AUTOSAR XML (schema 00047)
standard types defined: boolean_DataConstr, boolean, float32, sint16, uint16, uint32, uint8
package /Constants
  constant specification InitValue_SeatAxPosStrct: value-spec={short-label=InitValue_SeatAxPosStrct, fields=[seatID:SeatID_NULL, {short-label=seatPositionCounts, fields=[hdrstForeaft:0, hdrstHght:0, seatHght:0, seatForeaft:0, seatRcln:0, lmbrHzntl:0, lmbrVert:0, thighLeft:0, thighRight:0, cshnTlt:0, thorPvt:0, calfRst:0, foreaftExt:0, seatSwivel:0, centerStackConsole:0]}, {short-label=seatPositionPercent, fields=[hdrstForeaft:0, hdrstHght:0, seatHght:0, seatForeaft:0, seatRcln:0, lmbrHzntl:0, lmbrVert:0, thighLeft:0, thighRight:0, cshnTlt:0, thorPvt:0, calfRst:0, foreaftExt:0, seatSwivel:0, centerStackConsole:0]}, {short-label=seatPositionPhysicalUnits, fields=[hdrstForeaft:0, hdrstHght:0, seatHght:0, seatForeaft:0, seatRcln:0, lmbrHzntl:0, lmbrVert:0, thighLeft:0, thighRight:0, cshnTlt:0, thorPvt:0, calfRst:0, foreaftExt:0, seatSwivel:0, centerStackConsole:0]}]}
  constant specification InitValue_SeatAxisStatStrct: value-spec={short-label=InitValue_SeatAxisStatStrct, fields=[seatID:SeatID_NULL, hdrstForeaftStat:SeatAxisStatus_NULL, hdrstHghtStat:SeatAxisStatus_NULL, seatHghtStat:SeatAxisStatus_NULL, seatForeaftStat:SeatAxisStatus_NULL, seatRclnStat:SeatAxisStatus_NULL, lmbrHzntlStat:SeatAxisStatus_NULL, lmbrVertStat:SeatAxisStatus_NULL, thighLeftStat:SeatAxisStatus_NULL, thighRightStat:SeatAxisStatus_NULL, cshnTltStat:SeatAxisStatus_NULL, thorPvtStat:SeatAxisStatus_NULL, calfRstStat:SeatAxisStatus_NULL, foreaftExtStat:SeatAxisStatus_NULL, seatSwivelStat:SeatAxisStatus_NULL, centerConsoleStat:SeatAxisStatus_NULL]}
  constant specification InitValue_SeatsTargetAxisStruct: value-spec={short-label=InitValue_SeatsTargetAxisStruct, fields=[selectedSeatMenu:SeatID_NULL, {short-label=positionAxisID, fields=[firstRowSeatDriverPositionAxisID:MultifunctionAxes_MASSAGE_PATTERN_01, firstRowSeatPassengerPositionAxisID:MultifunctionAxes_MASSAGE_PATTERN_01, secondRowSeatDriverPositionAxisID:MultifunctionAxes_MASSAGE_PATTERN_01, secondRowSeatPassengerPositionAxisID:MultifunctionAxes_MASSAGE_PATTERN_01]}]}
package /DataConstraints
  range boolean_DataConstr1: raw 0..1
package /DataTypeMappingSets
  4 x data type mapping set:
    DataMappings  # Data Mappings
    FoundationSwDataMapping
    SeatMapping
      data-type-maps:
        application-data-type=ActuationDutyCycle, implementation-data-type=uint8
        application-data-type=ActuationDutyCycle1, implementation-data-type=uint8
        application-data-type=AvailSeatAxType, implementation-data-type=uint32
        application-data-type=AvailSeatBldrPos, implementation-data-type=uint8
        application-data-type=AvailSeatCtlType, implementation-data-type=uint8
        application-data-type=AvailSeatFldPtchType, implementation-data-type=uint8
        application-data-type=AvailStmsPtrn, implementation-data-type=uint16
        application-data-type=CafRst, implementation-data-type=sint16
        application-data-type=ForeaftExten, implementation-data-type=uint16
        application-data-type=Int16AbsoluteValue, implementation-data-type=uint16
        application-data-type=Int32CountValue, implementation-data-type=uint16
        application-data-type=ManPrsHoldStat, implementation-data-type=uint8
        application-data-type=MultifunctionAxes, implementation-data-type=uint8
        application-data-type=MvtDir, implementation-data-type=uint8
        application-data-type=RelPrio, implementation-data-type=uint16
        application-data-type=SeatAdjmt, implementation-data-type=sint16
        application-data-type=SeatAdjsmt, implementation-data-type=uint8
        application-data-type=SeatAft, implementation-data-type=uint16
        application-data-type=SeatAxPercent, implementation-data-type=uint8
        application-data-type=SeatAxPosCntStrct, implementation-data-type=SeatAxPosCntStrct
        application-data-type=SeatAxPosStrct, implementation-data-type=SeatAxPosStrct
        application-data-type=SeatAxStatStrct, implementation-data-type=SeatAxStatStrct
        application-data-type=SeatAxType, implementation-data-type=uint8
        application-data-type=SeatAxVal, implementation-data-type=sint16
        application-data-type=SeatAxisStatus, implementation-data-type=uint8
        application-data-type=SeatAxisType, implementation-data-type=uint8
        application-data-type=SeatBlMovmt, implementation-data-type=sint16
        application-data-type=SeatBldrPActl, implementation-data-type=uint8
        application-data-type=SeatBldrPDsply, implementation-data-type=uint8
        application-data-type=SeatBldrPos, implementation-data-type=uint8
        application-data-type=SeatBldrStatArr, implementation-data-type=SeatBldrStatArr
        application-data-type=SeatBldrStatStrct, implementation-data-type=SeatBldrStatStrct
        application-data-type=SeatClimtMde, implementation-data-type=uint8
        application-data-type=SeatClimtStatArr, implementation-data-type=SeatClimtStatArr
        application-data-type=SeatClimtStatStrct, implementation-data-type=SeatClimtStatStrct
        application-data-type=SeatCntToDeg, implementation-data-type=sint16
        application-data-type=SeatCntToMm, implementation-data-type=sint16
        application-data-type=SeatCntToPct, implementation-data-type=sint16
        application-data-type=SeatCpbltyArr, implementation-data-type=SeatCpbltyArr
        application-data-type=SeatCpbltyStrct, implementation-data-type=SeatCpbltyStrct
        application-data-type=SeatCtlChngStat, implementation-data-type=uint8
        application-data-type=SeatDegCnvrtOfstStrct, implementation-data-type=SeatDegCnvrtOfstStrct
        application-data-type=SeatDegCnvrtScalStrct, implementation-data-type=SeatDegCnvrtScalStrct
        application-data-type=SeatFaltStatStrct, implementation-data-type=SeatFltStatStrct
        application-data-type=SeatFldStat, implementation-data-type=uint8
        application-data-type=SeatFldStatArr, implementation-data-type=SeatFldStatArr
        application-data-type=SeatFldStatStrct, implementation-data-type=SeatFldStatStrct
        application-data-type=SeatFldType, implementation-data-type=uint8
        application-data-type=SeatFltStatArr, implementation-data-type=SeatFltStatArr
        application-data-type=SeatFoldStat, implementation-data-type=uint8
        application-data-type=SeatForeaft, implementation-data-type=sint16
        application-data-type=SeatHdrstStatArr, implementation-data-type=SeatHdrstStatArr
        application-data-type=SeatHdrstStatStrct, implementation-data-type=SeatHdrstStatStrct
        application-data-type=SeatID, implementation-data-type=uint8
        application-data-type=SeatID1, implementation-data-type=uint8
        application-data-type=SeatId2, implementation-data-type=uint8
        application-data-type=SeatLmbrMovmt, implementation-data-type=sint16
        application-data-type=SeatLmbrMovmt1, implementation-data-type=uint8
        application-data-type=SeatMMCnvrtOfstStrct, implementation-data-type=SeatMMCnvrtOfstStrct
        application-data-type=SeatMMCnvrtScalStrct, implementation-data-type=SeatMMCnvrtScalStrct
        application-data-type=SeatMvmtType, implementation-data-type=uint8
        application-data-type=SeatMvtDir, implementation-data-type=uint8
        application-data-type=SeatMvtType, implementation-data-type=uint8
        application-data-type=SeatOccStat, implementation-data-type=uint8
        application-data-type=SeatOccStatArr, implementation-data-type=SeatOccStatArr
        application-data-type=SeatOccStatStrct, implementation-data-type=SeatOccStatStrct
        application-data-type=SeatPctCnvrtOfstStrct, implementation-data-type=SeatPctCnvrtOfstStrct
        application-data-type=SeatPctCnvrtScalStrct, implementation-data-type=SeatPctCnvrtScalStrct
        application-data-type=SeatPosArr, implementation-data-type=SeatPosArr
        application-data-type=SeatPosDutCyclStrct, implementation-data-type=SeatPosDutCyclStrct
        application-data-type=SeatRcln, implementation-data-type=sint16
        application-data-type=SeatRecline, implementation-data-type=uint8
        application-data-type=SeatRelPrio, implementation-data-type=uint16
        application-data-type=SeatSetPoint, implementation-data-type=uint8
        application-data-type=SeatSetStat, implementation-data-type=sint16
        application-data-type=SeatSetStatArr, implementation-data-type=SeatSetngStatArr
        application-data-type=SeatSetStatStrct, implementation-data-type=SeatSetngStatStrct
        application-data-type=SeatSrvcSint16, implementation-data-type=sint16
        application-data-type=SeatSrvcUint16, implementation-data-type=uint16
        application-data-type=SeatSrvcUint32, implementation-data-type=uint32
        application-data-type=SeatSrvcUint8, implementation-data-type=uint8
        application-data-type=SeatStmsIntns, implementation-data-type=uint8
        application-data-type=SeatStmsMde, implementation-data-type=uint8
        application-data-type=SeatSwiv, implementation-data-type=uint16
        application-data-type=SeatSwtchMvtDir, implementation-data-type=uint8
        application-data-type=SeatsTargetAxisStruct, implementation-data-type=SeatsTargetAxisStruct
        application-data-type=Sint16, implementation-data-type=sint16
        application-data-type=StmsIntns, implementation-data-type=uint8
        application-data-type=StmsMde, implementation-data-type=uint8
        application-data-type=StmsPtrn, implementation-data-type=uint8
        application-data-type=StmsStatArr, implementation-data-type=StmsStatArr
        application-data-type=StmsStatStrct, implementation-data-type=StmsStatStrct
        application-data-type=Unit, implementation-data-type=uint8
        application-data-type=VehSpd, implementation-data-type=float32
        application-data-type=boolean, implementation-data-type=boolean
        application-data-type=mSecUint32, implementation-data-type=uint32
        application-data-type=Int16AbsoluteValue_n32768ton1, implementation-data-type=uint16
        application-data-type=SeatAxPosNoUntStrct, implementation-data-type=SeatAxPosNoUntStrct
        application-data-type=SeatPosUnitStrct, implementation-data-type=SeatPosUnitStrct
        application-data-type=SeatAxisStatStrct, implementation-data-type=SeatAxisStatStrct
        application-data-type=ActuationDutyCycle1_0to255, implementation-data-type=uint8
        application-data-type=ErrorStat, implementation-data-type=ErrorStat
        application-data-type=UInt16_0to500, implementation-data-type=uint16
    SeatSrvc: data-type-map{application-data-type=SeatCpbltyStrct, implementation-data-type=SeatCpbltyStrct}
package /DataTypes/ApplicationDataTypes
  10 x application array data type, all with category=ARRAY, sw-calibration-access=READ-ONLY:
    SeatBldrStatArr  # SeatBladderStatusArray
      element SeatBldrStatArr: category=STRUCTURE, type=SeatBldrStatStrct, array-size-semantics=FIXED-SIZE, max-number-of-elements=8
    SeatClimtStatArr  # SeatClimateStatusArray
      element SeatClimtStatArr: category=STRUCTURE, type=SeatClimtStatStrct, array-size-semantics=FIXED-SIZE, max-number-of-elements=8
    SeatCpbltyArr  # SeatCapability
      element SeatCpbltyArr: category=STRUCTURE, type=SeatCpbltyStrct, array-size-semantics=FIXED-SIZE, max-number-of-elements=8
    SeatFldStatArr  # SeatFoldStatusArray
      element SeatFldStatArr: category=STRUCTURE, type=SeatFldStatStrct, array-size-semantics=FIXED-SIZE, max-number-of-elements=8
    SeatFltStatArr  # SeatFaultStatusArray
      element SeatFltStatArr: category=STRUCTURE, type=SeatFaltStatStrct, array-size-semantics=FIXED-SIZE, max-number-of-elements=8
    SeatHdrstStatArr  # SeatHeadrestStatusArray
      element SeatHdrstStatArr: category=STRUCTURE, type=SeatHdrstStatStrct, array-size-semantics=FIXED-SIZE, max-number-of-elements=8
    SeatOccStatArr  # SeatOccupancyStatusArray
      element SeatOccStatArr: category=STRUCTURE, type=SeatOccStatStrct, array-size-semantics=FIXED-SIZE, max-number-of-elements=8
    SeatPosArr  # SeatPositionArray
      element SeatPosArr: category=STRUCTURE, type=SeatAxStatStrct, array-size-semantics=FIXED-SIZE, max-number-of-elements=8
    SeatSetStatArr  # SeatSettingStatusArray
      element SeatSetStatArr: category=STRUCTURE, type=SeatSetStatStrct, array-size-semantics=FIXED-SIZE, max-number-of-elements=8
    StmsStatArr  # SeatMassageStatusArray
      element StmsStatArr: category=STRUCTURE, type=StmsStatStrct, array-size-semantics=FIXED-SIZE, max-number-of-elements=8
  28 x application record data type, all with category=STRUCTURE, sw-calibration-access=READ-ONLY:
    SeatAxPosCntStrct  # SeatAxisStatus
      16 x application record element, all with category=VALUE:
        SeatID: type=SeatID  # SeatIdentifier
        HdrstForeaftCnt: type=SeatSrvcSint16
        HdrstHghtCnt: type=SeatSrvcSint16
        SeatHghtCnt: type=SeatSrvcSint16
        SeatForeaftCnt: type=SeatSrvcSint16
        SeatRclnCnt: type=SeatSrvcSint16
        LmbrHzntlCnt: type=SeatSrvcSint16
        LmbrVertCnt: type=SeatSrvcSint16
        ThighLeftCnt: type=SeatSrvcSint16
        ThighRightCnt: type=SeatSrvcSint16
        CshnTltCnt: type=SeatSrvcSint16
        ThorPvtCnt: type=SeatSrvcSint16
        CalfRstCnt: type=SeatSrvcSint16
        ForeaftExtCnt: type=SeatSrvcSint16
        SeatSwivelCnt: type=SeatSrvcSint16
        CenterStackConsoleCnt: type=SeatSrvcSint16
    SeatAxPosCntsStrct
      15 x application record element, all with category=VALUE, type=Int32CountValue:
        hdrstForeaft
        hdrstHght
        seatHght
        seatForeaft
        seatRcln
        lmbrHzntl
        lmbrVert
        thighLeft
        thighRight
        cshnTlt
        thorPvt
        calfRst
        foreaftExt
        seatSwivel
        centerStackConsole
    SeatAxPosNoUntStrct
      15 x application record element, all with category=VALUE, type=Int16AbsoluteValue_n32768ton1:
        hdrstForeaft
        hdrstHght
        seatHght
        seatForeaft
        seatRcln
        lmbrHzntl
        lmbrVert
        thighLeft
        thighRight
        cshnTlt
        thorPvt
        calfRst
        foreaftExt
        seatSwivel
        centerStackConsole
    SeatAxPosPhsclStrct
      15 x application record element, all with category=VALUE:
        hdrstForeaft: type=SeatAdjsmt
        hdrstHght: type=SeatAdjsmt
        seatHght: type=SeatAdjsmt
        seatForeaft: type=SeatAft
        seatRcln: type=SeatRecline
        lmbrHzntl: type=SeatLmbrMovmt1
        lmbrVert: type=SeatLmbrMovmt1
        thighLeft: type=SeatAdjsmt
        thighRight: type=SeatAdjsmt
        cshnTlt: type=SeatAdjsmt
        thorPvt: type=SeatAdjsmt
        calfRst: type=SeatRecline
        foreaftExt: type=ForeaftExten
        seatSwivel: type=SeatSwiv
        centerStackConsole: type=ForeaftExten
    SeatAxPosPrcntStrct
      15 x application record element, all with category=VALUE, type=SeatAxPercent:
        hdrstForeaft
        hdrstHght
        seatHght
        seatForeaft
        seatRcln
        lmbrHzntl
        lmbrVert
        thighLeft
        thighRight
        cshnTlt
        thorPvt
        calfRst
        foreaftExt
        seatSwivel
        centerStackConsole
    SeatAxPosStrct
      4 x application record element:
        seatID: category=VALUE, type=SeatID1
        seatPositionCounts: category=STRUCTURE, type=SeatAxPosCntsStrct
        seatPositionPercent: category=STRUCTURE, type=SeatAxPosPrcntStrct
        seatPositionPhysicalUnits: category=STRUCTURE, type=SeatAxPosPhsclStrct
    SeatAxStatStrct  # SeatAxisStatus
      18 x application record element, all with category=VALUE:
        SeatID: type=SeatID  # SeatIdentifier
        HdrstForeaft: type=SeatAdjmt  # HeadrestForeaft
        HdrstHght: type=SeatAdjmt  # HeadrestHeight
        SeatHght: type=SeatAdjmt  # SeatHeight
        SeatForeaft: type=SeatForeaft
        SeatRcln: type=SeatRcln  # SeatInclineRecline
        LmbrHzntl: type=SeatLmbrMovmt  # LumbarHorizontal
        LmbrVert: type=SeatLmbrMovmt  # LumbarVertical
        ThighLeft: type=SeatAdjmt
        ThighRight: type=SeatAdjmt
        TopLmbr: type=SeatLmbrMovmt  # TopLumbar
        MidLmbr: type=SeatLmbrMovmt  # MiddleLumbar
        LwrLmbr: type=SeatLmbrMovmt  # LowerLumbar
        LwrBl: type=SeatBlMovmt  # LowerBolster
        UpBl: type=SeatBlMovmt  # UpperBolster
        CshnTlt: type=SeatAdjmt  # CushionTilt
        TicPvt: type=SeatAdjmt  # ThoracicPivot
        CafRst: type=CafRst  # CalfRest
    SeatAxisStatStrct
      16 x application record element, all with category=VALUE:
        seatID: type=SeatID1
        hdrstForeaftStat: type=SeatAxisStatus
        hdrstHghtStat: type=SeatAxisStatus
        seatHghtStat: type=SeatAxisStatus
        seatForeaftStat: type=SeatAxisStatus
        seatRclnStat: type=SeatAxisStatus
        lmbrHzntlStat: type=SeatAxisStatus
        lmbrVertStat: type=SeatAxisStatus
        thighLeftStat: type=SeatAxisStatus
        thighRightStat: type=SeatAxisStatus
        cshnTltStat: type=SeatAxisStatus
        thorPvtStat: type=SeatAxisStatus
        calfRstStat: type=SeatAxisStatus
        foreaftExtStat: type=SeatAxisStatus
        seatSwivelStat: type=SeatAxisStatus
        centerConsoleStat: type=SeatAxisStatus
    SeatBldrStatStrct  # SeatBladderStatusStructure
      4 x application record element, all with category=VALUE:
        SeatId: type=SeatId2  # SeatIdentifier
        SeatBldrPos: type=SeatBldrPos  # SeatBladderPosition
        SeatBldrPActl: type=SeatBldrPActl  # SeatBladderPressureActual
        SeatBldrPDsply: type=SeatBldrPDsply  # SeatBladderPressureDisplay
    SeatClimtStatStrct  # SeatClimateStatusStructure
      application record element SeatId: category=VALUE, type=SeatId2  # SeatIdentifier
      application record element SeatClimtMde: category=VALUE, type=SeatClimtMde  # SeatClimateMode
      application record element SetPoint: category=VALUE, type=SeatSetPoint
    SeatCpbltyStrct  # SeatCapability
      7 x application record element:
        SeatID: category=VALUE, type=SeatID  # SeatIdentifier
        SeatPrsntStat: category=BOOLEAN, type=boolean  # SeatPresentStatus
        AvailSeatCtlType: category=VALUE, type=AvailSeatCtlType  # AvailableSeatControlType
        AvailSeatAxType: category=VALUE, type=AvailSeatAxType  # AvailableSeatAxisType
        AvailStmsPtrn: category=VALUE, type=AvailStmsPtrn  # AvailableSeatMessagePattern
        AvailSeatBldrPos: category=VALUE, type=AvailSeatBldrPos  # AvailableSeatBladderPosition
        AvailSeatFldPtchType: category=VALUE, type=AvailSeatFldPtchType  # AvailableSeatFoldPitchType
    SeatDegCnvrtOfstStrct
      15 x application record element, all with category=VALUE, type=SeatSrvcSint16:
        HdrstForeaftOfstDeg
        HdrstHghtOfstDeg
        SeatHghtOfstDeg
        SeatForeaftOfstDeg
        SeatRclnOfstDeg
        LmbrHzntlOfstDeg
        LmbrVertOfstDeg
        ThighLeftOfstDeg
        ThighRightOfstDeg
        CshnTltOfstDeg
        ThorPvtOfstDeg
        CalfRstOfstDeg
        ForeaftExtOfstDeg
        SeatSwivelOfstDeg
        CenterConsoleOfstDeg
    SeatDegCnvrtScalStrct
      15 x application record element, all with category=VALUE, type=SeatCntToDeg:
        HdrstForeaftScalDeg
        HdrstHghtScalDeg
        SeatHghtScalDeg
        SeatForeaftScalDeg
        SeatRclnScalDeg
        LmbrHzntlScalDeg
        LmbrVertScalDeg
        ThighLeftScalDeg
        ThighRightScalDeg
        CshnTltScalDeg
        ThorPvtScalDeg
        CalfRstScalDeg
        ForeaftExtScalDeg
        SeatSwivelScalDeg
        CenterConsoleScalDeg
    SeatFaltStatStrct  # SeatFaultStatusStructure
      7 x application record element, all with category=VALUE:
        SeatId: type=SeatId2  # SeatIdentifier
        SeatMovmtCtlFltStat: type=SeatCtlChngStat  # SeatMovementControlFaultStatus
        SeatFldCtlFltStat: type=SeatCtlChngStat  # SeatFoldControlFaultStatus
        SeatStmsCtrlFltStat: type=SeatCtlChngStat  # SeatMassageControlFaultStatus
        SeatClimtCtlFltStat: type=SeatCtlChngStat  # SeatClimateControlFaultStatus
        SeatBldrCtlFltStat: type=SeatCtlChngStat  # SeatBladderControlFaultStatus
        SeatHdrstClimtFltStat: type=SeatCtlChngStat  # SeatHeadrestControlFaultStatus
    SeatFldStatStrct  # SeatFoldStatusStructure
      application record element SeatId: category=VALUE, type=SeatId2  # SeatIdentifier
      application record element SeatFldStat: category=VALUE, type=SeatFldStat  # SeatFoldStatus
    SeatHdrstStatStrct  # SeatHeadrestStatusStructure
      application record element SeatId: category=VALUE, type=SeatId2  # SeatIdentifier
      application record element SetPoint: category=VALUE, type=SeatSetPoint
    SeatMMCnvrtOfstStrct
      15 x application record element, all with category=VALUE, type=SeatSrvcSint16:
        HdrstForeaftOfstMM
        HdrstHghtOfstMM
        SeatHghtOfstMM
        SeatForeaftOfstMM
        SeatRclnOfstMM
        LmbrHzntlOfstMM
        LmbrVertOfstMM
        ThighLeftOfstMM
        ThighRightOfstMM
        CshnTltOfstMM
        ThorPvtOfstMM
        CalfRstOfstMM
        ForeaftExtOfstMM
        SeatSwivelOfstMM
        CenterConsoleOfstMM
    SeatMMCnvrtScalStrct
      15 x application record element, all with category=VALUE, type=SeatCntToMm:
        HdrstForeaftScalMM
        HdrstHghtScalMM
        SeatHghtScalMM
        SeatForeaftScalMM
        SeatRclnScalMM
        LmbrHzntlScalMM
        LmbrVertScalMM
        ThighLeftScalMM
        ThighRightScalMM
        CshnTltScalMM
        ThorPvtScalMM
        CalfRstScalMM
        ForeaftExtScalMM
        SeatSwivelScalMM
        CenterConsoleScalMM
    SeatOccStatStrct  # SeatOccupancyStatusStructure
      application record element SeatId: category=VALUE, type=SeatId2  # SeatIdentifier
      application record element SeatOccStat: category=VALUE, type=SeatOccStat  # SeatOccupancyStatus
    SeatPctCnvrtOfstStrct
      15 x application record element, all with category=VALUE, type=SeatSrvcSint16:
        HdrstForeaftOfstPct
        HdrstHghtOfstPct
        SeatHghtOfstPct
        SeatForeaftOfstPct
        SeatRclnOfstPct
        LmbrHzntlOfstPct
        LmbrVertOfstPct
        ThighLeftOfstPct
        ThighRightOfstPct
        CshnTltOfstPct
        ThorPvtOfstPct
        CalfRstOfstPct
        ForeaftExtOfstPct
        SeatSwivelOfstPct
        CenterConsoleOfstPct
    SeatPctCnvrtScalStrct
      15 x application record element, all with category=VALUE, type=SeatCntToPct:
        HdrstForeaftScalPct
        HdrstHghtScalPct
        SeatHghtScalPct
        SeatForeaftScalPct
        SeatRclnScalPct
        LmbrHzntlScalPct
        LmbrVertScalPct
        ThighLeftScalPct
        ThighRightScalPct
        CshnTltScalPct
        ThorPvtScalPct
        CalfRstScalPct
        ForeaftExtScalPct
        SeatSwivelScalPct
        CenterConsoleScalPct
    SeatPosDutCyclStrct
      15 x application record element, all with category=VALUE, type=ActuationDutyCycle:
        HdrstForeaftDC
        HdrstHghtDC
        SeatHghtDC
        SeatForeaftDC
        SeatRclnDC
        LmbrHzntlDC
        LmbrVertDC
        ThighLeftDC
        ThighRightDC
        CshnTltDC
        ThorPvtDC
        CalfRstDC
        ForeaftExtDC
        SeatSwivelDC
        CenterConsoleDC
    SeatPosDutCyclStrct1
      15 x application record element, all with category=VALUE, type=ActuationDutyCycle1:
        hdrstForeaftDC
        hdrstHghtDC
        seatHghtDC
        seatForeaftDC
        seatRclnDC
        lmbrHzntlDC
        lmbrVertDC
        thighLeftDC
        thighRightDC
        cshnTltDC
        thorPvtDC
        calfRstDC
        foreaftExtDC
        seatSwivelDC
        centerConsoleDC
    SeatPosUnitStrct
      15 x application record element, all with category=VALUE, type=Unit:
        hdrstForeaftDC
        hdrstHghtDC
        seatHghtDC
        seatForeaftDC
        seatRclnDC
        lmbrHzntlDC
        lmbrVertDC
        thighLeftDC
        thighRightDC
        cshnTltDC
        thorPvtDC
        calfRstDC
        foreaftExtDC
        seatSwivelDC
        centerConsoleDC
    SeatSetStatStrct  # SeatSettingStatusStructure
      28 x application record element, all with category=VALUE:
        SeatId: type=SeatId2  # SeatIdentifier
        HdrstForeaft: type=SeatAdjmt  # HeadrestForeaft
        HdrstHght: type=SeatAdjmt  # HeadrestHeight
        SeatHght: type=SeatAdjmt  # SeatHeight
        SeatForeaft: type=SeatForeaft
        SeatRcln: type=SeatRcln  # SeatInclineRecline
        LmbrHzntl: type=SeatLmbrMovmt  # LumbarHorizontal
        LmbrVert: type=SeatLmbrMovmt  # LumbarVertical
        ThighLeft: type=SeatAdjmt
        ThighRight: type=SeatAdjmt
        TopLmbr: type=SeatLmbrMovmt  # TopLumbar
        MidLmbr: type=SeatLmbrMovmt  # MiddleLumbar
        LwrLmbr: type=SeatLmbrMovmt  # LowerLumbar
        LwrBl: type=SeatBlMovmt  # LowerBolster
        UpBl: type=SeatBlMovmt  # UpperBolster
        CshnTlt: type=SeatAdjmt  # CushionTilt
        TicPvt: type=SeatAdjmt  # ThoracicPivot
        CafRst: type=CafRst  # CalfRest
        SeatClimtMde: type=SeatClimtMde  # SeatClimateMode
        SeatClimtSetPoint: type=SeatSetPoint  # SeatClimateSetPoint
        StmsMde: type=StmsMde  # SeatMassageMode
        StmsPtrn: type=StmsPtrn  # SeatMassagePattern
        StmsIntns: type=StmsIntns  # SeatMassageIntensity
        SeatBldrPos: type=SeatBldrPos  # SeatBladderPosition
        SeatBldrPActl: type=SeatBldrPActl  # SeatBladderPressureActual
        SeatBldrPDsply: type=SeatBldrPDsply  # SeatBladderPressureDisplay
        SeatHdresClimtSetPoint: type=SeatSetPoint  # SeatHeadrestClimateSetPoint
        SeatFldStat: type=SeatFldStat  # SeatFoldStatus
    SeatsMultiFunctionAxesStruct
      4 x application record element, all with category=VALUE, type=MultifunctionAxes:
        firstRowSeatDriverPositionAxisID
        firstRowSeatPassengerPositionAxisID
        secondRowSeatDriverPositionAxisID
        secondRowSeatPassengerPositionAxisID
    SeatsTargetAxisStruct
      application record element selectedSeatMenu: category=VALUE, type=SeatID1
      application record element positionAxisID: category=STRUCTURE, type=SeatsMultiFunctionAxesStruct
    StmsStatStrct  # SeatMassageStatusStructure
      4 x application record element, all with category=VALUE:
        SeatId: type=SeatId2  # SeatIdentifier
        StmsMde: type=StmsMde  # SeatMassageMode
        StmsPtrn: type=StmsPtrn  # SeatMassagePattern
        StmsIntns: type=StmsIntns  # SeatMassageIntensity
  66 x app type, all with sw-calibration-access=READ-ONLY:
    ActuationDutyCycle: category=VALUE, compu {phys=raw; unit %DtyCyc}, data-constr=DC_ActuationDutyCycle
    ActuationDutyCycle1: category=VALUE, compu {phys=raw; unit %DtyCyc}, range phys 0..100, unit=%DtyCyc
    AvailSeatAxType: category=VALUE, compu {mask 1: 1=SEAT_HEADREST_FOREAFT_AVAIL, mask 2: 2=SEAT_HEADREST_HEIGHT_AVAIL, mask 4: 4=SEAT_HEIGHT_AVAIL, mask 8: 8=SEAT_FOREAFT_AVAIL, mask 16: 16=SEAT_INCLINE_RECLINE_AVAIL, mask 32: 32=SEAT_LUMBAR_HORIZONTAL_AVAIL, mask 64: 64=SEAT_LUMBAR_VERTICAL_AVAIL, mask 128: 128=SEAT_THIGH_LEFT_AVAIL, mask 256: 256=SEAT_THIGH_RIGHT_AVAIL, mask 512: 512=SEAT_TOP_LUMBAR_AVAIL, mask 1024: 1024=SEAT_MIDDLE_LUMBAR_AVAIL, mask 2048: 2048=SEAT_LOWER_LUMBAR_AVAIL, mask 4096: 4096=SEAT_LOWER_BOLSTER_AVAIL, mask 8192: 8192=SEAT_UPPER_BOLSTER_AVAIL, mask 16384: 16384=SEAT_CUSHION_TILT_AVAIL, mask 32768: 32768=SEAT_THORACIC_PIVOT_AVAIL, mask 65536: 65536=SEAT_CALF_REST_AVAIL} "Available Seat Axis Type"  # AvailableSeatAxisType
    AvailSeatBldrPos: category=VALUE, compu {mask 1: 1=BLADDER_TOP_LUMBAR_AVAIL, mask 2: 2=BLADDER_MIDDLE_LUMBAR_AVAIL, mask 4: 4=BLADDER_LOWER_LUMBAR_AVAIL, mask 8: 8=BLADDER_UPPER_BOLSTER_AVAIL, mask 16: 16=BLADDER_LOWER_BOLSTER_AVAIL} "Available Seat Bladder Position"  # AvailableSeatBladderPosition
    AvailSeatCtlType: category=VALUE, compu {mask 1: 1=MOVE_SEAT_CONTROL, mask 2: 2=SEAT_CLIMATE_CONTROL, mask 4: 4=HEADREST_CLIMATE_CONTROL, mask 8: 8=SEAT_MASSAGE_CONTROL, mask 16: 16=SEAT_BLADDER_CONTROL, mask 32: 32=SEAT_FOLD_CONTROL} "Available Seat Control Type"  # AvailableSeatControlType
    AvailSeatFldPtchType: category=VALUE, compu {mask 1: 1=POWER_FOLD_AVAIL, mask 2: 2=POWER_UNFOLD_AVAIL, mask 4: 4=MANUAL_FOLD_AVAIL, mask 8: 8=POWER_PITCH_AVAIL, mask 16: 16=POWER_UNPITCH_AVAIL, mask 32: 32=MANUAL_PITCH_AVAIL} "Available Seat Fold Pitch Type"  # AvailableSeatFoldPitchType
    AvailStmsPtrn: category=VALUE, compu {mask 1: 1=MASSAGE_LOWER_ROLLING_AVAIL, mask 2: 2=MASSAGE_UPPER_ROLLING_AVAIL, mask 4: 4=MASSAGE_CIRCULAR_CUSHION_AVAIL, mask 8: 8=MASSAGE_FULL_RECOVERY_AVAIL, mask 16: 16=MASSAGE_RELAXED_RECOVERY_AVAIL, mask 32: 32=MASSAGE_CIRCULAR_COMBO_AVAIL, mask 64: 64=MASSAGE_ZIG_ZAG_COMBO_AVAIL, mask 128: 128=MASSAGE_SWEEP_WAVE_AVAIL, mask 256: 256=MASSAGE_UP_WAVE_AVAIL, mask 512: 512=MASSAGE_PULSE_AVAIL} "Available Seat Message Pattern"  # AvailableSeatMessagePattern
    CafRst: category=VALUE, compu {phys=raw; unit <} "CalfRest"  # Calf Rest
    ForeaftExten: category=VALUE, compu {phys=raw-4000; unit mm}, range phys -8000..0, unit=mm
    Int16AbsoluteValue: category=VALUE, compu {phys=raw-32768}, range phys -65536..-1, unit=NoUnit
    Int32CountValue: category=VALUE, compu {phys=raw-32768; unit count}, range phys -65536..-1, unit=count
    ManPrsHoldStat: category=VALUE, compu {0=NULL, 1=INCREASE, 2=DECREASE, 3=TAP_INC, 4=STECLMNPRCOND_ACT_TIMEOUT}
    MultifunctionAxes:
      category=VALUE
      compu {0..9=MultifunctionAxes_MASSAGE_PATTERN_01..MultifunctionAxes_MASSAGE_PATTERN_010, 10=MultifunctionAxes_LOWER_LUMBAR, 11=MultifunctionAxes_MIDDLE_LUMBAR, 12=MultifunctionAxes_UPPER_LUMBAR, 13=MultifunctionAxes_LOWER_BOLSTER, 14=MultifunctionAxes_UPPER_BOLSTER, 15=MultifunctionAxes_LEFT_THIGH, 16=MultifunctionAxes_RIGHT_THIGH, 17=MultifunctionAxes_BOTH_THIGH, 18=MultifunctionAxes_HEADREST_HORIZONTAL, 19=MultifunctionAxes_HEADREST_VERTICAL, 20=MultifunctionAxes_CALF_RAISE, 21=MultifunctionAxes_THORACIC}
      range raw 0..21
      unit=NoUnit
    MvtDir: category=VALUE, compu {0=MVDIRENUM_FORE, 1=MVDIRENUM_AFT, 2=MVDIRENUM_INCLINE, 3=MVDIRENUM_RECLINE, 4=MVDIRENUM_INCREASE, 5=MVDIRENUM_DECREASE, 6=MVDIRENUM_UP, 7=MVDIRENUM_DOWN} "SeatMovementDirectionEnum"  # SeatMovementDirection
    RelPrio: category=VALUE  # RelativePriority
    SeatAdjmt: category=VALUE, compu {phys=raw; unit mm} "SeatAdjustment"  # SeatAdjustment
    SeatAdjsmt: category=VALUE, compu {phys=raw-60; unit mm}, range phys -120..0, unit=mm
    SeatAft: category=VALUE, compu {phys=raw-2000; unit mm}, range phys -4000..0, unit=mm
    SeatAxPercent: category=VALUE, compu {phys=raw; unit %}, range phys 0..100, unit=%
    SeatAxType: category=VALUE, compu {0=SEATAXTYPEENUM_SEAT_HEADREST_FOREAFT, 1=SEATAXTYPEENUM_SEAT_HEADREST_HEIGHT, 2=SEATAXTYPEENUM_SEAT_HEIGHT, 3=SEATAXTYPEENUM_SEAT_FOREAFT, 4=SEATAXTYPEENUM_SEAT_INCLINE_RECLINE, 5=SEATAXTYPEENUM_SEAT_LUMBAR_HORIZONTAL, 6=SEATAXTYPEENUM_SEAT_LUMBAR_VERTICAL, 7=SEATAXTYPEENUM_SEAT_THIGH_LEFT, 8=SEATAXTYPEENUM_SEAT_THIGH_RIGHT, 9=SEATAXTYPEENUM_SEAT_TOP_LUMBAR, 10=SEATAXTYPEENUM_SEAT_MIDDLE_LUMBAR, 11=SEATAXTYPEENUM_SEAT_LOWER_LUMBAR, 12=SEATAXTYPEENUM_SEAT_LOWER_BOLSTER, 13=SEATAXTYPEENUM_SEAT_UPPER_BOLSTER, 14=SEATAXTYPEENUM_SEAT_CUSHION_TILT, 15=SEATAXTYPEENUM_SEAT_THORACIC_PIVOT, 16=SEATAXTYPEENUM_SEAT_CALF_REST} "SeatAxisTypeEnum"  # SeatAxisType
    SeatAxVal: category=VALUE, compu {phys=raw; unit mm} "IntegerInt16"  # SeatAxisValueType
    SeatAxisStatus: category=VALUE, compu {0=SeatAxisStatus_NULL, 1=SeatAxisStatus_BUSY, 2=SeatAxisStatus_IDLE, 3=SeatAxisStatus_INTERRUPTED, 4=SeatAxisStatus_STALLED, 5=SeatAxisStatus_NOT_EQUIPPED, 6=SeatAxisStatus_UNKNOWN, 7=SeatAxisStatus_FAULTY}, range raw 0..7, unit=NoUnit
    SeatAxisType:
      category=VALUE
      compu {0=SeatAxisType_NULL, 1=SeatAxisType_HEADREST_FOREAFT, 2=SeatAxisType_HEADREST_HEIGHT, 3=SeatAxisType_SEAT_HEIGHT, 4=SeatAxisType_SEAT_FOREAFT, 5=SeatAxisType_INCLINE_RECLINE, 6=SeatAxisType_LUMBAR_HORIZONTAL, 7=SeatAxisType_LUMBAR_VERTICAL, 8=SeatAxisType_THIGH_LEFT, 9=SeatAxisType_THIGH_RIGHT, 10=SeatAxisType_THIGH_BOTH, 11=SeatAxisType_CUSHION_TILT, 12=SeatAxisType_THORACIC_PIVOT, 13=SeatAxisType_CALF_REST, 14=SeatAxisType_FORE_AFT_EXT, 15=SeatAxisType_SWIVEL, 16=SeatAxisType_CUSHION_FLIP, 17=SeatAxisType_CENTER_CONSOLE}
      range raw 0..17
      unit=NoUnit
    SeatBlMovmt: category=VALUE, compu {phys=raw; unit mm} "SeatBolsterMovement"  # SeatBolsterMovement
    SeatBldrPActl: category=VALUE, compu {phys=raw; unit %} "SeatBladderPressureActual"  # SeatBladderPressureActual
    SeatBldrPDsply: category=VALUE, compu {phys=raw*10; unit %} "SeatBladderPressureDisplay"  # SeatBladderPressureDisplay
    SeatBldrPos: category=VALUE, compu {0=SEATBLDRPOSENUM_BLADDER_NONE_SELECTED, 1=SEATBLDRPOSENUM_BLADDER_TOP_LUMBAR, 2=SEATBLDRPOSENUM_BLADDER_MIDDLE_LUMBAR, 3=SEATBLDRPOSENUM_BLADDER_LOWER_LUMBAR, 4=SEATBLDRPOSENUM_BLADDER_UPPER_BOLSTER, 5=SEATBLDRPOSENUM_BLADDER_LOWER_BOLSTER} "SeatBladderPositionEnum"  # SeatBladderPosition
    SeatClimtMde: category=VALUE, compu {0=SEATCLIMTMDEENUM_CLIMATE_OFF, 1=SEATCLIMTMDEENUM_HEAT, 2=SEATCLIMTMDEENUM_COOL} "SeatClimateModeEnum"  # SeatClimateMode
    SeatCntToDeg: category=VALUE, compu {phys=raw*0.0001; unit Cnt/Deg}
    SeatCntToMm: category=VALUE, compu {phys=raw*0.0001; unit Cnt/Mm}
    SeatCntToPct: category=VALUE, compu {phys=raw*0.0001; unit Cnt/Pct}
    SeatCtlChngStat: category=VALUE, compu {0=SEATCTLCHNGSTATENUM_SEAT_CHNG_STAT_NA, 1=SEATCTLCHNGSTATENUM_SEAT_CHNG_STAT_NOT_FAULTED, 2=SEATCTLCHNGSTATENUM_SEAT_CHNG_STAT_FAULTED, 3=SEATCTLCHNGSTATENUM_SAET_CHNG_STAT_UNKNOWN} "SeatControlChangeStatusEnum"  # SeatControlChangeStatus
    SeatFldStat: category=VALUE, compu {0=SEATFLDSTATENUM_SEAT_FOLD_STAT_NA, 1=SEATFLDSTATENUM_SEAT_FOLDED, 2=SEATFLDSTATENUM_SEAT_UNFOLDED, 3=SEATFLDSTATENUM_SEAT_PITCHED_SLID, 4=SEATFLDSTATENUM_SEAT_UNPITCHED_SLID} "SeatFoldStatusEnum"  # SeatFoldStatus
    SeatFldType: category=VALUE, compu {0=SEATFLDTYPEENUM_POWER_FOLD, 1=SEATFLDTYPEENUM_POWER_UNFOLD, 2=SEATFLDTYPEENUM_POWER_PITCH_SLIDE, 3=SEATFLDTYPEENUM_POWER_UNPITCH_UNSLIDE, 4=SEATFLDTYPEENUM_NO_FOLD_ACTION} "SeatFoldTypesEnum"  # SeatFoldTypes
    SeatFoldStat: category=VALUE, compu {0=SeatFoldStat_NULL, 1=SeatFoldStat_RETURNED, 2=SeatFoldStat_MANUAL_FOLD, 3=SeatFoldStat_POWER_FOLDING, 4=SeatFoldStat_POWER_UNFOLDING, 5=SeatFoldStat_POWERFOLD_FOLDED, 6=SeatFoldStat_PITCH_SLIDE_DEPLOYING, 7=SeatFoldStat_PITCH_SLIDE_RETURNING, 8=SeatFldStat_PITCH_SLIDE_DEPLOYED, 9=SeatFldStat_STOPPED}
    SeatForeaft: category=VALUE, compu {phys=raw; unit mm} "Seat forward and backward movement"  # Seat forward and backward movement
    SeatID: category=VALUE, compu {0=NONE, 1=DRIVER, 2=PASSENGER, 3=SECOND_ROW_DRIVER, 4=SECOND_ROW_PASSENGER, 5=SECOND_ROW_MIDDLE, 6=THIRD_ROW_DRIVER, 7=THIRD_ROW_PASSENGER, 8=THIRD_ROW_MIDDLE, 9=CENTER_CONSOLE}
    SeatID1: category=VALUE, compu {0=SeatID_NULL, 1=SeatID_DRIVER, 2=SeatID_PASSENGER, 3=SeatID_SECOND_ROW_DRIVER, 4=SeatID_SECOND_ROW_PASSENGER, 5=SeatID_SECOND_ROW_MIDDLE, 6=SeatID_THIRD_ROW_DRIVER, 7=SeatID_THIRD_ROW_PASSENGER, 8=SeatID_THIRD_ROW_BOTH, 9=SeatID_CENTER_CONSOLE}, range raw 0..9, unit=NoUnit
    SeatId2: category=VALUE, compu {0=SEATIDENUM_DRIVER, 1=SEATIDENUM_PASSENGER, 2=SEATIDENUM_SECOND_ROW_LH, 3=SEATIDENUM_SECOND_ROW_MIDDLE, 4=SEATIDENUM_SECOND_ROW_RH, 5=SEATIDENUM_THIRD_ROW_LH, 6=SEATIDENUM_THIRD_ROW_MIDDLE, 7=SEATIDENUM_THIRD_ROW_RH} "SeatIdentifierEnum"  # SeatIdentifier
    SeatLmbrMovmt: category=VALUE, compu {phys=raw; unit mm} "SeatLumbarMovement"  # SeatLumbarMovement
    SeatLmbrMovmt1: category=VALUE, compu {phys=raw-50; unit mm}, range phys -100..0, unit=mm
    SeatMvmtType: category=VALUE, compu {0=SeatMvmtType_NULL, 1=SeatMvmtType_RELATIVE, 2=SeatMvmtType_ABSOLUTE, 3=SeatMvmtType_CANCEL}, range raw 0..3, unit=NoUnit
    SeatMvtDir: category=VALUE, compu {0=SeatMvtDir_NULL, 1=SeatMvtDir_INCREASE, 2=SeatMvtDir_DECREASE}, range raw 0..2, unit=NoUnit
    SeatMvtType: category=VALUE, compu {0=SEATMVTTYPEENUM_RELATIVE, 1=SEATMVTTYPEENUM_ABSOLUTE, 2=SEATMVTTYPEENUM_INCREMENTAL, 3=SEATMVTTYPEENUM_CONTINUOUS, 4=SEATMVTTYPEENUM_CANCEL} "SeatMovementTypeEnum"  # SeatMovementType
    SeatOccStat: category=VALUE, compu {0=SEATOCCSTATENUM_EMPTY, 1=SEATOCCSTATENUM_OCCUPIED, 2=SEATOCCSTATENUM_UNKNOWN, 3=SEATOCCSTATENUM_FAULT_STATUS} "SeatOccupancyStatusEnum"  # SeatOccupancyStatus
    SeatRcln: category=VALUE, compu {phys=raw; unit <} "SeatRecline"  # Seat Recline
    SeatRecline: category=VALUE, compu {phys=raw-90; unit degreeAngle}, range phys -180..0, unit=<
    SeatRelPrio: category=VALUE, compu {phys=raw}, range phys 0..65535, unit=NoUnit
    SeatSetPoint: category=VALUE, compu {0=SEATSETPOINTENUM_BLOWER_SPEED_SETPOINT_OFF, 1=SEATSETPOINTENUM_BLOWER_SPEED_LOW, 2=SEATSETPOINTENUM_BLOWER_SPEED_MEDIUM, 3=SEATSETPOINTENUM_BLOWER_SPEED_HIGH} "SeatSetPointsEnum"
    SeatSetStat: category=VALUE, compu {0=SEATSETSTAT_SEATID, 1=SEATSETSTAT_HDRSTFOREAFT, 2=SEATSETSTAT_HDRSTHGHT, 3=SEATSETSTAT_SEATHGHT, 4=SEATSETSTAT_SEATFOREAFT, 5=SEATSETSTAT_SEATRCLN, 6=SEATSETSTAT_LMBRHZNTL, 7=SEATSETSTAT_LMBRVERT, 8=SEATSETSTAT_THIGHLEFT, 9=SEATSETSTAT_THIGHRIGHT, 10=SEATSETSTAT_TOPLMBR, 11=SEATSETSTAT_MIDLMBR, 12=SEATSETSTAT_LWRLMBR, 13=SEATSETSTAT_LWRBL, 14=SEATSETSTAT_UPBL, 15=SEATSETSTAT_CSHNTLT, 17=SEATSETSTAT_TICPVT, 18=SEATSETSTAT_CAFRST, 19=SEATSETSTAT_SEATCLIMTMDE, 20=SEATSETSTAT_SEATCLIMTSETPOINT, 21=SEATSETSTAT_STMSMDE, 22=SEATSETSTAT_STMSPTRN, 23=SEATSETSTAT_SEATBLDRPOS, 24=SEATSETSTAT_SEATBLDRPACTL, 25=SEATSETSTAT_SEATBLDRPDSPLY, 26=SEATSETSTAT_SEATHDRESCLIMTSETPOINT, 27=SEATSETSTAT_SEATFLDTYPE} "SeatSettingStatus"  # SeatSettingStatus
    SeatSrvcSint16: category=VALUE, compu {identical}, data-constr=DC_SeatSrvcSint16
    SeatSrvcUint16: category=VALUE, compu {identical}
    SeatSrvcUint32: category=VALUE, compu {identical}
    SeatSrvcUint8: category=VALUE, compu {identical}
    SeatStmsIntns: category=VALUE, compu {0=SeatStmsIntns_MASSAGE_INTENSITY_OFF, 1=SeatStmsIntns_MASSAGE_INTENSITY_LOW, 2=SeatStmsIntns_MASSAGE_INTENSITY_MEDIUM, 3=SeatStmsIntns_MASSAGE_INTENSITY_HIGH}
    SeatStmsMde: category=VALUE, compu {0=SeatStmsMde_MASSAGE_OFF, 1=SeatStmsMde_MASSAGE_ON}
    SeatSwiv: category=VALUE, compu {phys=raw-180; unit degreeAngle}, range phys -360..0, unit=<
    SeatSwtchMvtDir: category=VALUE, compu {0=SEATSWTCHMVTDIR_SEATFORE, 1=SEATSWTCHMVTDIR_SEATAFT, 2=SEATSWTCHMVTDIR_SEATINCLINE, 3=SEATSWTCHMVTDIR_SEATRECLINE, 4=SEATSWTCHMVTDIR_SEATINCREASE, 5=SEATSWTCHMVTDIR_SEATDECREASE, 6=SEATSWTCHMVTDIR_SEATUP, 7=SEATSWTCHMVTDIR_SEATDOWN}
    Sint16: category=VALUE
    StmsIntns: category=VALUE, compu {0=STMSINTNSENUM_MASSAGE_INTENSITY_OFF, 1=STMSINTNSENUM_MASSAGE_INTENSITY_LOW, 2=STMSINTNSENUM_MASSAGE_INTENSITY_MEDIUM, 3=STMSINTNSENUM_MASSAGE_INTENSITY_HIGH} "SeatMassageIntensityEnum"  # SeatMassageIntensity
    StmsMde: category=VALUE, compu {0=STMSMDEENUM_MASSAGE_OFF, 1=STMSMDEENUM_MASSAGE_ON} "SeatMassageModeEnum"  # SeatMassageMode
    StmsPtrn: category=VALUE, compu {0=STMSPTRNENUM_MASSAGE_PATTERN_NONE, 1=STMSPTRNENUM_MASSAGE_LOWER_ROLLING, 2=STMSPTRNENUM_MASSAGE_UPPER_ROLLING, 3=STMSPTRNENUM_MASSAGE_CIRCULAR_CUSHION, 4=STMSPTRNENUM_MASSAGE_FULL_RECOVERY, 5=STMSPTRNENUM_MASSAGE_RELAXED_RECOVERY, 6=STMSPTRNENUM_MASSAGE_CIRCULAR_COMBO, 7=STMSPTRNENUM_MASSAGE_ZIG_ZAG_COMBO, 8=STMSPTRNENUM_MASSAGE_SWEEP_WAVE, 9=STMSPTRNENUM_MASSAGE_UP_WAVE, 10=STMSPTRNENUM_MASSAGE_PULSE} "SeatMassagePatternEnum"  # SeatMassagePattern
    Unit: category=VALUE, compu {0=Unit_MM, 1=Unit_PRCNT, 2=Unit_DEG, 3=Unit_COUNT, 4=Unit_ENUM}, range raw 0..4, unit=NoUnit
    VehSpd: category=VALUE, compu-method=Identcl, range phys 0..500, unit=km/h
    boolean: category=BOOLEAN, compu {0=FALSE, 1=TRUE}, unit=NoUnit
    mSecUint32: category=VALUE, compu {phys=raw; unit ms} "Second", unit=ms
package /DataTypes/BaseTypes
  sw addr method CALIB_AUXILLARY_BODY: memory-allocation-keyword-policy=ADDR-METHOD-SHORT-NAME, section-type=CALPRM
  sw addr method CODE: memory-allocation-keyword-policy=ADDR-METHOD-SHORT-NAME, section-type=CODE
  base type uint161: category=FIXED_LENGTH, base-type-size=16, base-type-encoding=NONE, native-declaration=uint16
  base type uint81: category=FIXED_LENGTH, base-type-size=8, base-type-encoding=NONE, native-declaration=uint8
package /DataTypes/ImplementationDataTypes
  36 x impl type:
    SeatAxPosCntStrct: category=STRUCTURE
      16 x element, all with category=TYPE_REFERENCE:
        SeatID: implementation-data-type=uint8
        HdrstForeaftCnt: implementation-data-type=sint16
        HdrstHghtCnt: implementation-data-type=sint16
        SeatHghtCnt: implementation-data-type=sint16
        SeatForeaftCnt: implementation-data-type=sint16
        SeatRclnCnt: implementation-data-type=sint16
        LmbrHzntlCnt: implementation-data-type=sint16
        LmbrVertCnt: implementation-data-type=sint16
        ThighLeftCnt: implementation-data-type=sint16
        ThighRightCnt: implementation-data-type=sint16
        CshnTltCnt: implementation-data-type=sint16
        ThorPvtCnt: implementation-data-type=sint16
        CalfRstCnt: implementation-data-type=sint16
        ForeaftExtCnt: implementation-data-type=sint16
        SeatSwivelCnt: implementation-data-type=sint16
        CenterStackConsoleCnt: implementation-data-type=sint16
    SeatAxPosCntsStrct: category=STRUCTURE
      15 x element, all with category=TYPE_REFERENCE, implementation-data-type=uint161:
        hdrstForeaft
        hdrstHght
        seatHght
        seatForeaft
        seatRcln
        lmbrHzntl
        lmbrVert
        thighLeft
        thighRight
        cshnTlt
        thorPvt
        calfRst
        foreaftExt
        seatSwivel
        centerStackConsole
    SeatAxPosPhsclStrct: category=STRUCTURE
      15 x element, all with category=TYPE_REFERENCE:
        hdrstForeaft: implementation-data-type=uint81
        hdrstHght: implementation-data-type=uint81
        seatHght: implementation-data-type=uint81
        seatForeaft: implementation-data-type=uint161
        seatRcln: implementation-data-type=uint81
        lmbrHzntl: implementation-data-type=uint81
        lmbrVert: implementation-data-type=uint81
        thighLeft: implementation-data-type=uint81
        thighRight: implementation-data-type=uint81
        cshnTlt: implementation-data-type=uint81
        thorPvt: implementation-data-type=uint81
        calfRst: implementation-data-type=uint81
        foreaftExt: implementation-data-type=uint161
        seatSwivel: implementation-data-type=uint161
        centerStackConsole: implementation-data-type=uint161
    SeatAxPosPrcntStrct: category=STRUCTURE
      15 x element, all with category=TYPE_REFERENCE, implementation-data-type=uint81:
        hdrstForeaft
        hdrstHght
        seatHght
        seatForeaft
        seatRcln
        lmbrHzntl
        lmbrVert
        thighLeft
        thighRight
        cshnTlt
        thorPvt
        calfRst
        foreaftExt
        seatSwivel
        centerStackConsole
    SeatAxPosStrct: category=STRUCTURE
      4 x element, all with category=TYPE_REFERENCE:
        seatID: implementation-data-type=uint81
        seatPositionCounts: implementation-data-type=SeatAxPosCntsStrct
        seatPositionPercent: implementation-data-type=SeatAxPosPrcntStrct
        seatPositionPhysicalUnits: implementation-data-type=SeatAxPosPhsclStrct
    SeatAxStatStrct: category=STRUCTURE  # Seat Axis Status Structure
      18 x element:
        SeatID
        HdrstForeaft
        HdrstHght
        SeatHght
        SeatForeaft
        SeatRcln
        LmbrHzntl
        LmbrVert
        ThighLeft
        ThighRight
        TopLmbr
        MidLmbr
        LwrLmbr
        LwrBl
        UpBl
        CshnTlt
        TicPvt
        CafRst
    SeatBldrStatArr: category=ARRAY  # SeatBladderStatusArray
      element SeatBldrStatArr: array-size=8, array-size-semantics=FIXED-SIZE, implementation-data-type=SeatBldrStatStrct
    SeatBldrStatStrct: category=STRUCTURE  # SeatBladderStatusStructure
      4 x element:
        SeatId
        SeatBldrPos
        SeatBldrPActl
        SeatBldrPDsply
    SeatClimtStatArr: category=ARRAY  # SeatClimateStatusArray
      element SeatClimtStatArr: array-size=8, array-size-semantics=FIXED-SIZE, implementation-data-type=SeatClimtStatStrct
    SeatClimtStatStrct: category=STRUCTURE  # SeatClimateStatusStructure
      element SeatId
      element SeatClimtMde
      element SetPoint
    SeatCpbltyArr: category=ARRAY  # SeatCapabilityArray
      element SeatCpbltyArr: array-size=8, array-size-semantics=FIXED-SIZE, implementation-data-type=SeatCpbltyStrct
    SeatCpbltyStrct: category=STRUCTURE  # SeatCapability
      7 x element:
        SeatID
        SeatPrsntStat  # Boolean has the value space required to support the mathematical concept of binary-valued logic: {true, false}.
        AvailSeatCtlType
        AvailSeatAxType
        AvailStmsPtrn
        AvailSeatBldrPos
        AvailSeatFldPtchType
    SeatDegCnvrtOfstStrct: category=STRUCTURE
      15 x element:
        HdrstForeaftOfstDeg
        HdrstHghtOfstDeg
        SeatHghtOfstDeg
        SeatForeaftOfstDeg
        SeatRclnOfstDeg
        LmbrHzntlOfstDeg
        LmbrVertOfstDeg
        ThighLeftOfstDeg
        ThighRightOfstDeg
        CshnTltOfstDeg
        ThorPvtOfstDeg
        CalfRstOfstDeg
        ForeaftExtOfstDeg
        SeatSwivelOfstDeg
        CenterConsoleOfstDeg
    SeatDegCnvrtScalStrct: category=STRUCTURE
      15 x element:
        HdrstForeaftScalDeg
        HdrstHghtScalDeg
        SeatHghtScalDeg
        SeatForeaftScalDeg
        SeatRclnScalDeg
        LmbrHzntlScalDeg
        LmbrVertScalDeg
        ThighLeftScalDeg
        ThighRightScalDeg
        CshnTltScalDeg
        ThorPvtScalDeg
        CalfRstScalDeg
        ForeaftExtScalDeg
        SeatSwivelScalDeg
        CenterConsoleScalDeg
    SeatFldStatArr: category=ARRAY  # SeatFoldStatusArray
      element SeatFldStatArr: array-size=8, array-size-semantics=FIXED-SIZE, implementation-data-type=SeatFldStatStrct
    SeatFldStatStrct: category=STRUCTURE  # SeatFoldStatusStructure
      element SeatId
      element SeatFldStat
    SeatFltStatArr: category=ARRAY  # SeatFaultStatusArray
      element SeatFltStatArr: array-size=8, array-size-semantics=FIXED-SIZE, implementation-data-type=SeatFltStatStrct
    SeatFltStatStrct: category=STRUCTURE  # SeatFaultStausStructure
      7 x element:
        SeatId
        SeatMovmtCtlFltStat
        SeatFldCtlFltStat
        SeatStmsCtrlFltStat
        SeatClimtCtlFltStat
        SeatBldrCtlFltStat
        SeatHdrstClimtFltStat
    SeatHdrstStatArr: category=ARRAY  # SeatHeadrestStatusArray
      element SeatHdrstStatArr: array-size=8, array-size-semantics=FIXED-SIZE, implementation-data-type=SeatHdrstStatStrct
    SeatHdrstStatStrct: category=STRUCTURE  # SeatHeadrestStatusStructure
      element SeatId
      element SetPoint
    SeatMMCnvrtOfstStrct: category=STRUCTURE
      15 x element:
        HdrstForeaftOfstMM
        HdrstHghtOfstMM
        SeatHghtOfstMM
        SeatForeaftOfstMM
        SeatRclnOfstMM
        LmbrHzntlOfstMM
        LmbrVertOfstMM
        ThighLeftOfstMM
        ThighRightOfstMM
        CshnTltOfstMM
        ThorPvtOfstMM
        CalfRstOfstMM
        ForeaftExtOfstMM
        SeatSwivelOfstMM
        CenterConsoleOfstMM
    SeatMMCnvrtScalStrct: category=STRUCTURE
      15 x element:
        HdrstForeaftScalMM
        HdrstHghtScalMM
        SeatHghtScalMM
        SeatForeaftScalMM
        SeatRclnScalMM
        LmbrHzntlScalMM
        LmbrVertScalMM
        ThighLeftScalMM
        ThighRightScalMM
        CshnTltScalMM
        ThorPvtScalMM
        CalfRstScalMM
        ForeaftExtScalMM
        SeatSwivelScalMM
        CenterConsoleScalMM
    SeatOccStatArr: category=ARRAY  # SeatOccupancyStatusArray
      element SeatOccStatArr: array-size=8, array-size-semantics=FIXED-SIZE, implementation-data-type=SeatOccStatStrct
    SeatOccStatStrct: category=STRUCTURE  # SeatOccupancyStatusStructure
      element SeatId
      element SeatOccStat
    SeatPctCnvrtOfstStrct: category=STRUCTURE
      15 x element:
        HdrstForeaftOfstPct
        HdrstHghtOfstPct
        SeatHghtOfstPct
        SeatForeaftOfstPct
        SeatRclnOfstPct
        LmbrHzntlOfstPct
        LmbrVertOfstPct
        ThighLeftOfstPct
        ThighRightOfstPct
        CshnTltOfstPct
        ThorPvtOfstPct
        CalfRstOfstPct
        ForeaftExtOfstPct
        SeatSwivelOfstPct
        CenterConsoleOfstPct
    SeatPctCnvrtScalStrct: category=STRUCTURE
      15 x element:
        HdrstForeaftScalPct
        HdrstHghtScalPct
        SeatHghtScalPct
        SeatForeaftScalPct
        SeatRclnScalPct
        LmbrHzntlScalPct
        LmbrVertScalPct
        ThighLeftScalPct
        ThighRightScalPct
        CshnTltScalPct
        ThorPvtScalPct
        CalfRstScalPct
        ForeaftExtScalPct
        SeatSwivelScalPct
        CenterConsoleScalPct
    SeatPosArr: category=ARRAY  # SeatPositionArray
      element SeatPosArr: array-size=8, array-size-semantics=FIXED-SIZE, implementation-data-type=SeatAxStatStrct
    SeatPosDutCyclStrct: category=STRUCTURE
      15 x element, all with category=TYPE_REFERENCE, implementation-data-type=uint8:
        HdrstForeaftDC
        HdrstHghtDC
        SeatHghtDC
        SeatForeaftDC
        SeatRclnDC
        LmbrHzntlDC
        LmbrVertDC
        ThighLeftDC
        ThighRightDC
        CshnTltDC
        ThorPvtDC
        CalfRstDC
        ForeaftExtDC
        SeatSwivelDC
        CenterConsoleDC
    SeatSetngStatArr: category=ARRAY  # SeatSettingStatusArray
      element SeatSetngStatArr: array-size=8, array-size-semantics=FIXED-SIZE, implementation-data-type=SeatSetngStatStrct
    SeatSetngStatStrct: category=STRUCTURE  # SeatSettingStatusStructure
      28 x element:
        SeatId
        HdrstForeaft
        HdrstHght
        SeatHght
        SeatForeaft
        SeatRcln
        LmbrHzntl
        LmbrVert
        ThighLeft
        ThighRight
        TopLmbr
        MidLmbr
        LwrLmbr
        LwrBl
        UpBl
        CshnTlt
        TicPvt
        CafRst
        SeatClimtMde
        SeatClimtSetPoint
        StmsMde
        StmsPtrn
        StmsIntns
        SeatBldrPos
        SeatBldrPActl
        SeatBldrPDsply
        SeatHdresClimtSetPoint
        SeatFldStat
    SeatsMultiFunctionAxesStruct: category=STRUCTURE
      4 x element, all with category=TYPE_REFERENCE, implementation-data-type=uint81:
        firstRowSeatDriverPositionAxisID
        firstRowSeatPassengerPositionAxisID
        secondRowSeatDriverPositionAxisID
        secondRowSeatPassengerPositionAxisID
    SeatsTargetAxisStruct: category=STRUCTURE
      element selectedSeatMenu: implementation-data-type=uint81
      element positionAxisID: implementation-data-type=SeatsMultiFunctionAxesStruct
    StmsStatArr: category=ARRAY  # SeatMassageStatusArray
      element StmsStatArr: array-size=8, array-size-semantics=FIXED-SIZE, implementation-data-type=StmsStatStrct
    StmsStatStrct: category=STRUCTURE  # SeatMassageStatusStructure
      4 x element:
        SeatId
        StmsMde
        StmsPtrn
        StmsIntns
    uint161: category=VALUE, base-type=uint161, range raw 0..65535
    uint81: category=VALUE, base-type=uint81, range raw 0..255
package /DataTypes/Units
  17 x unit, all with factor-si-to-unit=1:
    CntPerDeg: display-name=Cnt/Deg, offset-si-to-unit=0  # Count per Degree
    CntPerMM: display-name=Cnt/Mm, offset-si-to-unit=0  # Count per Mm
    CntPerPct: display-name=Cnt/Pct, offset-si-to-unit=0  # Count per Percent
    KmPerH: display-name=km/h, offset-si-to-unit=0  # kilometer per hour
    Millimeter: display-name=mm, offset-si-to-unit=0
    Millimeter1: display-name=mm, offset-si-to-unit=-1
    NoUnit: display-name=NoUnit, offset-si-to-unit=0
    NoUnit1: display-name=NoUnit, offset-si-to-unit=0
    PcDtyCyc: display-name=%DtyCyc, offset-si-to-unit=0  # Percent Duty Cycle
    PcDtyCyc1: display-name=%DtyCyc, offset-si-to-unit=-1
    Percentage: display-name=%, offset-si-to-unit=0
    Percentage1: display-name=%, offset-si-to-unit=-1
    count: display-name=count, offset-si-to-unit=0
    count1: display-name=count, offset-si-to-unit=-1
    deg: display-name=<, offset-si-to-unit=0  # Degree(Angle)
    deg1: display-name=degreeAngle, offset-si-to-unit=-1
    msec: display-name=ms, offset-si-to-unit=0  # Milli Second
package /SoftwareTypes/ComponentTypes
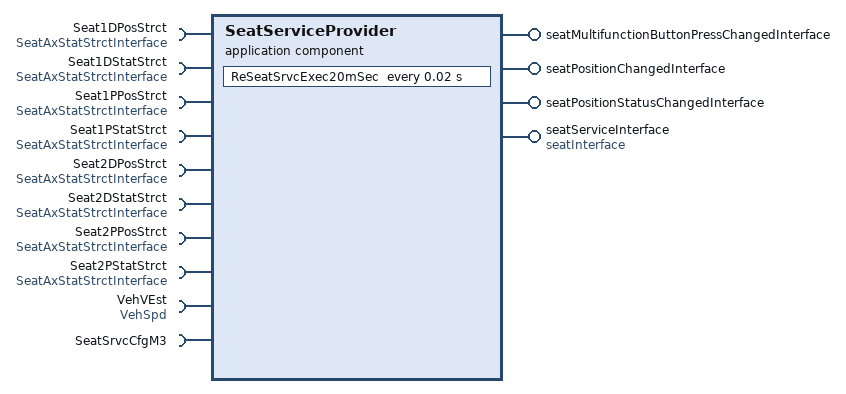
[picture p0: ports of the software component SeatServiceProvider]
  application sw component type SeatServiceProvider  # Seat service is a software component that exposes the capabilities of all seats in the vehicle and publish seat settings (on change) to in-vehicle modules and external entities.
    9 x require port:
      Seat1DPosStrct: nonqueued-receiver-com-spec{data-element=DeSeatAxPosStrct, init-value={short-label=DefaultInitValue_SeatAxPosCntStrct, fields=[NONE, 0, 0, 0, 0, 0, 0, 0, 0, 0, 0, 0, 0, 0, 0, 0]}}, required-interface=SeatAxStatStrctInterface
      Seat1DStatStrct: nonqueued-receiver-com-spec{data-element=DeSeatAxStatStrct, init-value={short-label=DefaultInitValue_SeatAxisStatStrct, fields=[SeatID_NULL, SeatAxisStatus_NULL, SeatAxisStatus_NULL, SeatAxisStatus_NULL, SeatAxisStatus_NULL, SeatAxisStatus_NULL, SeatAxisStatus_NULL, SeatAxisStatus_NULL, SeatAxisStatus_NULL, SeatAxisStatus_NULL, SeatAxisStatus_NULL, SeatAxisStatus_NULL, SeatAxisStatus_NULL, SeatAxisStatus_NULL, SeatAxisStatus_NULL, SeatAxisStatus_NULL]}}, required-interface=SeatAxStatStrctInterface
      Seat1PPosStrct: nonqueued-receiver-com-spec{data-element=DeSeatAxPosStrct, init-value={short-label=DefaultInitValue_SeatAxPosCntStrct, fields=[NONE, 0, 0, 0, 0, 0, 0, 0, 0, 0, 0, 0, 0, 0, 0, 0]}}, required-interface=SeatAxStatStrctInterface
      Seat1PStatStrct: nonqueued-receiver-com-spec{data-element=DeSeatAxStatStrct, init-value={short-label=DefaultInitValue_SeatAxisStatStrct, fields=[SeatID_NULL, SeatAxisStatus_NULL, SeatAxisStatus_NULL, SeatAxisStatus_NULL, SeatAxisStatus_NULL, SeatAxisStatus_NULL, SeatAxisStatus_NULL, SeatAxisStatus_NULL, SeatAxisStatus_NULL, SeatAxisStatus_NULL, SeatAxisStatus_NULL, SeatAxisStatus_NULL, SeatAxisStatus_NULL, SeatAxisStatus_NULL, SeatAxisStatus_NULL, SeatAxisStatus_NULL]}}, required-interface=SeatAxStatStrctInterface
      Seat2DPosStrct: nonqueued-receiver-com-spec{data-element=DeSeatAxPosStrct, init-value={short-label=DefaultInitValue_SeatAxPosCntStrct, fields=[NONE, 0, 0, 0, 0, 0, 0, 0, 0, 0, 0, 0, 0, 0, 0, 0]}}, required-interface=SeatAxStatStrctInterface
      Seat2DStatStrct: nonqueued-receiver-com-spec{data-element=DeSeatAxStatStrct, init-value={short-label=DefaultInitValue_SeatAxisStatStrct, fields=[SeatID_NULL, SeatAxisStatus_NULL, SeatAxisStatus_NULL, SeatAxisStatus_NULL, SeatAxisStatus_NULL, SeatAxisStatus_NULL, SeatAxisStatus_NULL, SeatAxisStatus_NULL, SeatAxisStatus_NULL, SeatAxisStatus_NULL, SeatAxisStatus_NULL, SeatAxisStatus_NULL, SeatAxisStatus_NULL, SeatAxisStatus_NULL, SeatAxisStatus_NULL, SeatAxisStatus_NULL]}}, required-interface=SeatAxStatStrctInterface
      Seat2PPosStrct: nonqueued-receiver-com-spec{data-element=DeSeatAxPosStrct, init-value={short-label=DefaultInitValue_SeatAxPosCntStrct, fields=[NONE, 0, 0, 0, 0, 0, 0, 0, 0, 0, 0, 0, 0, 0, 0, 0]}}, required-interface=SeatAxStatStrctInterface
      Seat2PStatStrct: nonqueued-receiver-com-spec{data-element=DeSeatAxStatStrct, init-value={short-label=DefaultInitValue_SeatAxisStatStrct, fields=[SeatID_NULL, SeatAxisStatus_NULL, SeatAxisStatus_NULL, SeatAxisStatus_NULL, SeatAxisStatus_NULL, SeatAxisStatus_NULL, SeatAxisStatus_NULL, SeatAxisStatus_NULL, SeatAxisStatus_NULL, SeatAxisStatus_NULL, SeatAxisStatus_NULL, SeatAxisStatus_NULL, SeatAxisStatus_NULL, SeatAxisStatus_NULL, SeatAxisStatus_NULL, SeatAxisStatus_NULL]}}, required-interface=SeatAxStatStrctInterface
      VehVEst: nonqueued-receiver-com-spec{data-element=DeVal, init-value=0}, required-interface=VehSpd
    4 x provide port:
      seatMultifunctionButtonPressChangedInterface: provided-interface=seatMultifunctionButtonPressChangedInterface
      seatPositionChangedInterface: provided-interface=seatPositionChangedInterface
      seatPositionStatusChangedInterface: provided-interface=seatPositionStatusChangedInterface
      seatServiceInterface: provided-com-specs=[{operation=moveSeatAutomatic, queue-length=1}, {operation=moveSeatManual, queue-length=1}], provided-interface=seatInterface
    require port SeatSrvcCfgM3: required-interface=SeatSrvcCfgM3
    behavior SeatServiceProvider_ib: data-type-mapping=[SeatMapping, SeatSrvc], handle-termination-and-restart=NO-SUPPORT, included-data-type-set=data-type=[ActuationDutyCycle, ErrorStat, SeatAxisStatus, SeatSrvcSint16]
      init event EvSeatSrvcInit: start-on-event=ReSeatSrvcInit
      operation invoked event EvMoveSeatAutomatic: start-on-event=ReMoveSeatAutomatic, operation=seatServiceInterface.moveSeatAutomatic
      operation invoked event EvMoveSeatManual: start-on-event=ReMoveSeatManual, operation=seatServiceInterface.moveSeatManual
      timing event EvSeatSrvcExec20mSec: start-on-event=ReSeatSrvcExec20mSec, period=0.02
      explicit-inter-runnable-variables:
        20 x data, all with sw-calibration-access=READ-ONLY:
          IrvActuationDutyCycleMan: category=VALUE, type=ActuationDutyCycle1_0to255, init-value=0 %DtyCyc
          IrvSeat1DAutoDCRqStrct: category=STRUCTURE, type=SeatPosDutCyclStrct, init-value={short-label=DefaultInitValue_SeatPosDutCyclStrct, fields=[0 %DtyCyc, 0 %DtyCyc, 0 %DtyCyc, 0 %DtyCyc, 0 %DtyCyc, 0 %DtyCyc, 0 %DtyCyc, 0 %DtyCyc, 0 %DtyCyc, 0 %DtyCyc, 0 %DtyCyc, 0 %DtyCyc, 0 %DtyCyc, 0 %DtyCyc, 0 %DtyCyc]}
          IrvSeat1DAutoPosRqStrct: category=STRUCTURE, type=SeatAxPosCntStrct, init-value={short-label=DefaultInitValue_SeatAxPosCntStrct, fields=[NONE, 0, 0, 0, 0, 0, 0, 0, 0, 0, 0, 0, 0, 0, 0, 0]}
          IrvSeat1DManDCRqStrct: category=STRUCTURE, type=SeatPosDutCyclStrct, init-value={short-label=DefaultInitValue_SeatPosDutCyclStrct, fields=[0 %DtyCyc, 0 %DtyCyc, 0 %DtyCyc, 0 %DtyCyc, 0 %DtyCyc, 0 %DtyCyc, 0 %DtyCyc, 0 %DtyCyc, 0 %DtyCyc, 0 %DtyCyc, 0 %DtyCyc, 0 %DtyCyc, 0 %DtyCyc, 0 %DtyCyc, 0 %DtyCyc]}
          IrvSeat1DManPosRqStrct: category=STRUCTURE, type=SeatAxPosCntStrct, init-value={short-label=DefaultInitValue_SeatAxPosCntStrct, fields=[NONE, 0, 0, 0, 0, 0, 0, 0, 0, 0, 0, 0, 0, 0, 0, 0]}
          IrvSeat1PAutoDCRqStrct: category=STRUCTURE, type=SeatPosDutCyclStrct, init-value={short-label=DefaultInitValue_SeatPosDutCyclStrct, fields=[0 %DtyCyc, 0 %DtyCyc, 0 %DtyCyc, 0 %DtyCyc, 0 %DtyCyc, 0 %DtyCyc, 0 %DtyCyc, 0 %DtyCyc, 0 %DtyCyc, 0 %DtyCyc, 0 %DtyCyc, 0 %DtyCyc, 0 %DtyCyc, 0 %DtyCyc, 0 %DtyCyc]}
          IrvSeat1PAutoPosRqStrct: category=STRUCTURE, type=SeatAxPosCntStrct, init-value={short-label=DefaultInitValue_SeatAxPosCntStrct, fields=[NONE, 0, 0, 0, 0, 0, 0, 0, 0, 0, 0, 0, 0, 0, 0, 0]}
          IrvSeat1PManDCRqStrct: category=STRUCTURE, type=SeatPosDutCyclStrct, init-value={short-label=DefaultInitValue_SeatPosDutCyclStrct, fields=[0 %DtyCyc, 0 %DtyCyc, 0 %DtyCyc, 0 %DtyCyc, 0 %DtyCyc, 0 %DtyCyc, 0 %DtyCyc, 0 %DtyCyc, 0 %DtyCyc, 0 %DtyCyc, 0 %DtyCyc, 0 %DtyCyc, 0 %DtyCyc, 0 %DtyCyc, 0 %DtyCyc]}
          IrvSeat1PManPosRqStrct: category=STRUCTURE, type=SeatAxPosCntStrct, init-value={short-label=DefaultInitValue_SeatAxPosCntStrct, fields=[NONE, 0, 0, 0, 0, 0, 0, 0, 0, 0, 0, 0, 0, 0, 0, 0]}
          IrvSeat2DAutoDCRqStrct: category=STRUCTURE, type=SeatPosDutCyclStrct, init-value={short-label=DefaultInitValue_SeatPosDutCyclStrct, fields=[0 %DtyCyc, 0 %DtyCyc, 0 %DtyCyc, 0 %DtyCyc, 0 %DtyCyc, 0 %DtyCyc, 0 %DtyCyc, 0 %DtyCyc, 0 %DtyCyc, 0 %DtyCyc, 0 %DtyCyc, 0 %DtyCyc, 0 %DtyCyc, 0 %DtyCyc, 0 %DtyCyc]}
          IrvSeat2DAutoPosRqStrct: category=STRUCTURE, type=SeatAxPosCntStrct, init-value={short-label=DefaultInitValue_SeatAxPosCntStrct, fields=[NONE, 0, 0, 0, 0, 0, 0, 0, 0, 0, 0, 0, 0, 0, 0, 0]}
          IrvSeat2DManDCRqStrct: category=STRUCTURE, type=SeatPosDutCyclStrct, init-value={short-label=DefaultInitValue_SeatPosDutCyclStrct, fields=[0 %DtyCyc, 0 %DtyCyc, 0 %DtyCyc, 0 %DtyCyc, 0 %DtyCyc, 0 %DtyCyc, 0 %DtyCyc, 0 %DtyCyc, 0 %DtyCyc, 0 %DtyCyc, 0 %DtyCyc, 0 %DtyCyc, 0 %DtyCyc, 0 %DtyCyc, 0 %DtyCyc]}
          IrvSeat2DManPosRqStrct: category=STRUCTURE, type=SeatAxPosCntStrct, init-value={short-label=DefaultInitValue_SeatAxPosCntStrct, fields=[NONE, 0, 0, 0, 0, 0, 0, 0, 0, 0, 0, 0, 0, 0, 0, 0]}
          IrvSeat2PAutoDCRqStrct: category=STRUCTURE, type=SeatPosDutCyclStrct, init-value={short-label=DefaultInitValue_SeatPosDutCyclStrct, fields=[0 %DtyCyc, 0 %DtyCyc, 0 %DtyCyc, 0 %DtyCyc, 0 %DtyCyc, 0 %DtyCyc, 0 %DtyCyc, 0 %DtyCyc, 0 %DtyCyc, 0 %DtyCyc, 0 %DtyCyc, 0 %DtyCyc, 0 %DtyCyc, 0 %DtyCyc, 0 %DtyCyc]}
          IrvSeat2PAutoPosRqStrct: category=STRUCTURE, type=SeatAxPosCntStrct, init-value={short-label=DefaultInitValue_SeatAxPosCntStrct, fields=[NONE, 0, 0, 0, 0, 0, 0, 0, 0, 0, 0, 0, 0, 0, 0, 0]}
          IrvSeat2PManDCRqStrct: category=STRUCTURE, type=SeatPosDutCyclStrct, init-value={short-label=DefaultInitValue_SeatPosDutCyclStrct, fields=[0 %DtyCyc, 0 %DtyCyc, 0 %DtyCyc, 0 %DtyCyc, 0 %DtyCyc, 0 %DtyCyc, 0 %DtyCyc, 0 %DtyCyc, 0 %DtyCyc, 0 %DtyCyc, 0 %DtyCyc, 0 %DtyCyc, 0 %DtyCyc, 0 %DtyCyc, 0 %DtyCyc]}
          IrvSeat2PManPosRqStrct: category=STRUCTURE, type=SeatAxPosCntStrct, init-value={short-label=DefaultInitValue_SeatAxPosCntStrct, fields=[NONE, 0, 0, 0, 0, 0, 0, 0, 0, 0, 0, 0, 0, 0, 0, 0]}
          IrvSeatAxisTypeMan: category=VALUE, type=SeatAxisType, init-value=SeatAxisType_NULL
          IrvSeatIDMan: category=VALUE, type=SeatID1, init-value=SeatID_NULL
          IrvSeatMvtDirMan: category=VALUE, type=SeatMvtDir, init-value=SeatMvtDir_NULL
      4 x runnable:
        ReMoveSeatAutomatic
          data-read-access:
            access IN_VehVEst_DeVal: accessed-variable=VehVEst.DeVal
          data-receive-point-by-arguments:
            8 x access:
              IN_Seat1DPosStrct_DeSeatAxPosStrct: accessed-variable=Seat1DPosStrct.DeSeatAxPosStrct
              IN_Seat1DStatStrct_DeSeatAxStatStrct: accessed-variable=Seat1DStatStrct.DeSeatAxStatStrct
              IN_Seat1PPosStrct_DeSeatAxPosStrct: accessed-variable=Seat1PPosStrct.DeSeatAxPosStrct
              IN_Seat1PStatStrct_DeSeatAxStatStrct: accessed-variable=Seat1PStatStrct.DeSeatAxStatStrct
              IN_Seat2DPosStrct_DeSeatAxPosStrct: accessed-variable=Seat2DPosStrct.DeSeatAxPosStrct
              IN_Seat2DStatStrct_DeSeatAxStatStrct: accessed-variable=Seat2DStatStrct.DeSeatAxStatStrct
              IN_Seat2PPosStrct_DeSeatAxPosStrct: accessed-variable=Seat2PPosStrct.DeSeatAxPosStrct
              IN_Seat2PStatStrct_DeSeatAxStatStrct: accessed-variable=Seat2PStatStrct.DeSeatAxStatStrct
          written-local-variables:
            8 x access:
              WV_IrvSeat1DAutoDCRqStrct: accessed-variable=IrvSeat1DAutoDCRqStrct
              WV_IrvSeat1DAutoPosRqStrct: accessed-variable=IrvSeat1DAutoPosRqStrct
              WV_IrvSeat1PAutoDCRqStrct: accessed-variable=IrvSeat1PAutoDCRqStrct
              WV_IrvSeat1PAutoPosRqStrct: accessed-variable=IrvSeat1PAutoPosRqStrct
              WV_IrvSeat2DAutoDCRqStrct: accessed-variable=IrvSeat2DAutoDCRqStrct
              WV_IrvSeat2DAutoPosRqStrct: accessed-variable=IrvSeat2DAutoPosRqStrct
              WV_IrvSeat2PAutoDCRqStrct: accessed-variable=IrvSeat2PAutoDCRqStrct
              WV_IrvSeat2PAutoPosRqStrct: accessed-variable=IrvSeat2PAutoPosRqStrct
        ReMoveSeatManual
          data-read-access:
            access IN_VehVEst_DeVal: accessed-variable=VehVEst.DeVal
          data-receive-point-by-arguments:
            8 x access:
              IN_Seat1DPosStrct_DeSeatAxPosStrct: accessed-variable=Seat1DPosStrct.DeSeatAxPosStrct
              IN_Seat1DStatStrct_DeSeatAxStatStrct: accessed-variable=Seat1DStatStrct.DeSeatAxStatStrct
              IN_Seat1PPosStrct_DeSeatAxPosStrct: accessed-variable=Seat1PPosStrct.DeSeatAxPosStrct
              IN_Seat1PStatStrct_DeSeatAxStatStrct: accessed-variable=Seat1PStatStrct.DeSeatAxStatStrct
              IN_Seat2DPosStrct_DeSeatAxPosStrct: accessed-variable=Seat2DPosStrct.DeSeatAxPosStrct
              IN_Seat2DStatStrct_DeSeatAxStatStrct: accessed-variable=Seat2DStatStrct.DeSeatAxStatStrct
              IN_Seat2PPosStrct_DeSeatAxPosStrct: accessed-variable=Seat2PPosStrct.DeSeatAxPosStrct
              IN_Seat2PStatStrct_DeSeatAxStatStrct: accessed-variable=Seat2PStatStrct.DeSeatAxStatStrct
          written-local-variables:
            12 x access:
              WV_IrvActuationDutyCycleMan: accessed-variable=IrvActuationDutyCycleMan
              WV_IrvSeat1DManDCRqStrct: accessed-variable=IrvSeat1DManDCRqStrct
              WV_IrvSeat1DManPosRqStrct: accessed-variable=IrvSeat1DManPosRqStrct
              WV_IrvSeat1PManDCRqStrct: accessed-variable=IrvSeat1PManDCRqStrct
              WV_IrvSeat1PManPosRqStrct: accessed-variable=IrvSeat1PManPosRqStrct
              WV_IrvSeat2DManDCRqStrct: accessed-variable=IrvSeat2DManDCRqStrct
              WV_IrvSeat2DManPosRqStrct: accessed-variable=IrvSeat2DManPosRqStrct
              WV_IrvSeat2PManDCRqStrct: accessed-variable=IrvSeat2PManDCRqStrct
              WV_IrvSeat2PManPosRqStrct: accessed-variable=IrvSeat2PManPosRqStrct
              WV_IrvSeatAxisTypeMan: accessed-variable=IrvSeatAxisTypeMan
              WV_IrvSeatIDMan: accessed-variable=IrvSeatIDMan
              WV_IrvSeatMvtDirMan: accessed-variable=IrvSeatMvtDirMan
        ReSeatSrvcExec20mSec: sw-addr-method=CODE
          data-receive-point-by-arguments:
            4 x access:
              IN_Seat1DPosStrct_DeSeatAxPosStrct: accessed-variable=Seat1DPosStrct.DeSeatAxPosStrct
              IN_Seat1PPosStrct_DeSeatAxPosStrct: accessed-variable=Seat1PPosStrct.DeSeatAxPosStrct
              IN_Seat2DPosStrct_DeSeatAxPosStrct: accessed-variable=Seat2DPosStrct.DeSeatAxPosStrct
              IN_Seat2PPosStrct_DeSeatAxPosStrct: accessed-variable=Seat2PPosStrct.DeSeatAxPosStrct
          read-local-variables:
            20 x access:
              RV_IrvActuationDutyCycleMan: accessed-variable=IrvActuationDutyCycleMan
              RV_IrvSeat1DAutoDCRqStrct: accessed-variable=IrvSeat1DAutoDCRqStrct
              RV_IrvSeat1DAutoPosRqStrct: accessed-variable=IrvSeat1DAutoPosRqStrct
              RV_IrvSeat1DManDCRqStrct: accessed-variable=IrvSeat1DManDCRqStrct
              RV_IrvSeat1DManPosRqStrct: accessed-variable=IrvSeat1DManPosRqStrct
              RV_IrvSeat1PAutoDCRqStrct: accessed-variable=IrvSeat1PAutoDCRqStrct
              RV_IrvSeat1PAutoPosRqStrct: accessed-variable=IrvSeat1PAutoPosRqStrct
              RV_IrvSeat1PManDCRqStrct: accessed-variable=IrvSeat1PManDCRqStrct
              RV_IrvSeat1PManPosRqStrct: accessed-variable=IrvSeat1PManPosRqStrct
              RV_IrvSeat2DAutoDCRqStrct: accessed-variable=IrvSeat2DAutoDCRqStrct
              RV_IrvSeat2DAutoPosRqStrct: accessed-variable=IrvSeat2DAutoPosRqStrct
              RV_IrvSeat2DManDCRqStrct: accessed-variable=IrvSeat2DManDCRqStrct
              RV_IrvSeat2DManPosRqStrct: accessed-variable=IrvSeat2DManPosRqStrct
              RV_IrvSeat2PAutoDCRqStrct: accessed-variable=IrvSeat2PAutoDCRqStrct
              RV_IrvSeat2PAutoPosRqStrct: accessed-variable=IrvSeat2PAutoPosRqStrct
              RV_IrvSeat2PManDCRqStrct: accessed-variable=IrvSeat2PManDCRqStrct
              RV_IrvSeat2PManPosRqStrct: accessed-variable=IrvSeat2PManPosRqStrct
              RV_IrvSeatAxisTypeMan: accessed-variable=IrvSeatAxisTypeMan
              RV_IrvSeatIDMan: accessed-variable=IrvSeatIDMan
              RV_IrvSeatMvtDirMan: accessed-variable=IrvSeatMvtDirMan
        ReSeatSrvcInit: sw-addr-method=CODE
          written-local-variables:
            8 x access:
              WV_IrvSeat1DManDCRqStrct: accessed-variable=IrvSeat1DManDCRqStrct
              WV_IrvSeat1DManPosRqStrct: accessed-variable=IrvSeat1DManPosRqStrct
              WV_IrvSeat1PManDCRqStrct: accessed-variable=IrvSeat1PManDCRqStrct
              WV_IrvSeat1PManPosRqStrct: accessed-variable=IrvSeat1PManPosRqStrct
              WV_IrvSeat2DManDCRqStrct: accessed-variable=IrvSeat2DManDCRqStrct
              WV_IrvSeat2DManPosRqStrct: accessed-variable=IrvSeat2DManPosRqStrct
              WV_IrvSeat2PManDCRqStrct: accessed-variable=IrvSeat2PManDCRqStrct
              WV_IrvSeat2PManPosRqStrct: accessed-variable=IrvSeat2PManPosRqStrct
package /SoftwareTypes/Interfaces
  client server interface seatInterface
    4 x operation:
      moveSeatAutomatic
        5 x arg, all with direction=IN:
          seatAxVal: category=STRUCTURE, type=SeatAxPosNoUntStrct
          seatMvtType: category=VALUE, type=SeatMvmtType
          physicalUnit: category=STRUCTURE, type=SeatPosUnitStrct
          actuationDutyCycle: category=STRUCTURE, type=SeatPosDutCyclStrct
          seatRelPrio: category=VALUE, type=SeatRelPrio
      moveSeatManual
        5 x arg, all with category=VALUE, direction=IN:
          seatID: type=SeatID1
          seatAxType: type=SeatAxisType
          seatMvtDir: type=SeatMvtDir
          actuationDutyCycle: type=ActuationDutyCycle1
          seatRelPrio: type=SeatRelPrio
      querySeatPosition
        4 x arg:
          seatID: category=VALUE, type=SeatID1, direction=IN
          units: category=STRUCTURE, type=SeatPosUnitStrct, direction=IN
          seatAxVal: category=STRUCTURE, type=SeatAxPosNoUntStrct, direction=OUT
          seatAxStatus: category=STRUCTURE, type=SeatAxisStatStrct, direction=OUT
      updateTargetAxisRequest
        arg seatID: category=VALUE, type=SeatID1, direction=IN
        arg targetAxisFunctions: category=VALUE, type=MultifunctionAxes, direction=IN
  parameter interface SeatSrvcCfgM3
    65 x parameter data prototype, all with sw-addr-method=CALIB_AUXILLARY_BODY, sw-calibration-access=READ-WRITE:
      Seat1DDegCnvrtOfstM3: category=STRUCTURE, type=SeatDegCnvrtOfstStrct, init-value={short-label=InitValue_SeatMMCnvrtOfstStrct, fields=[0, 0, 0, 0, 0, 0, 0, 0, 0, 0, 0, 0, 0, 0, 0]}
      Seat1DDegCnvrtScalM3: category=STRUCTURE, type=SeatDegCnvrtScalStrct, init-value={short-label=InitValue_SeatMMCnvrtScalStrct, fields=[1, 1, 1, 1, 1, 1, 1, 1, 1, 1, 1, 1, 1, 1, 1]}
      Seat1DMMCnvrtOfstM3: category=STRUCTURE, type=SeatMMCnvrtOfstStrct, init-value={short-label=InitValue_SeatMMCnvrtOfstStrct, fields=[0, 0, 0, 0, 0, 0, 0, 0, 0, 0, 0, 0, 0, 0, 0]}
      Seat1DMMCnvrtScalM3: category=STRUCTURE, type=SeatMMCnvrtScalStrct, init-value={short-label=InitValue_SeatMMCnvrtScalStrct, fields=[1, 1, 1, 1, 1, 1, 1, 1, 1, 1, 1, 1, 1, 1, 1]}
      Seat1DMaxPosM3: category=STRUCTURE, type=SeatAxPosCntStrct, init-value={short-label=InitValue_SeatAxPosCntStrct, fields=[0, 0, 0, 0, 0, 0, 0, 0, 0, 0, 0, 0, 0, 0, 0, 0]}
      Seat1DMinPosM3: category=STRUCTURE, type=SeatAxPosCntStrct, init-value={short-label=InitValue_SeatAxPosCntStrct, fields=[0, 0, 0, 0, 0, 0, 0, 0, 0, 0, 0, 0, 0, 0, 0, 0]}
      Seat1DPctCnvrtOfstM3: category=STRUCTURE, type=SeatPctCnvrtOfstStrct, init-value={short-label=InitValue_SeatMMCnvrtOfstStrct, fields=[0, 0, 0, 0, 0, 0, 0, 0, 0, 0, 0, 0, 0, 0, 0]}
      Seat1DPctCnvrtScalM3: category=STRUCTURE, type=SeatPctCnvrtScalStrct, init-value={short-label=InitValue_SeatMMCnvrtScalStrct, fields=[1, 1, 1, 1, 1, 1, 1, 1, 1, 1, 1, 1, 1, 1, 1]}
      Seat1DPrsHoldDecM3: category=STRUCTURE, type=SeatAxPosCntStrct, init-value={short-label=InitValue_SeatAxPosCntStrct, fields=[0, 0, 0, 0, 0, 0, 0, 0, 0, 0, 0, 0, 0, 0, 0, 0]}
      Seat1DPrsHoldIncM3: category=STRUCTURE, type=SeatAxPosCntStrct, init-value={short-label=InitValue_SeatAxPosCntStrct, fields=[0, 0, 0, 0, 0, 0, 0, 0, 0, 0, 0, 0, 0, 0, 0, 0]}
      Seat1DPrsHoldThldM3: category=VALUE, type=SeatSrvcUint16, init-value=0
      Seat1DTapDecM3: category=STRUCTURE, type=SeatAxPosCntStrct, init-value={short-label=InitValue_SeatAxPosCntStrct, fields=[0, 0, 0, 0, 0, 0, 0, 0, 0, 0, 0, 0, 0, 0, 0, 0]}
      Seat1DTapIncM3: category=STRUCTURE, type=SeatAxPosCntStrct, init-value={short-label=InitValue_SeatAxPosCntStrct, fields=[0, 0, 0, 0, 0, 0, 0, 0, 0, 0, 0, 0, 0, 0, 0, 0]}
      Seat1DTapThldM3: category=STRUCTURE, type=SeatAxPosCntStrct, init-value={short-label=InitValue_SeatAxPosCntStrct, fields=[0, 0, 0, 0, 0, 0, 0, 0, 0, 0, 0, 0, 0, 0, 0, 0]}
      Seat1DVehSpdThldM3: category=VALUE, type=SeatSrvcUint16, init-value=0
      Seat1PDegCnvrtOfstM3: category=STRUCTURE, type=SeatDegCnvrtOfstStrct, init-value={short-label=InitValue_SeatMMCnvrtOfstStrct, fields=[0, 0, 0, 0, 0, 0, 0, 0, 0, 0, 0, 0, 0, 0, 0]}
      Seat1PDegCnvrtScalM3: category=STRUCTURE, type=SeatDegCnvrtScalStrct, init-value={short-label=InitValue_SeatMMCnvrtScalStrct, fields=[1, 1, 1, 1, 1, 1, 1, 1, 1, 1, 1, 1, 1, 1, 1]}
      Seat1PMMCnvrtOfstM3: category=STRUCTURE, type=SeatMMCnvrtOfstStrct, init-value={short-label=InitValue_SeatMMCnvrtOfstStrct, fields=[0, 0, 0, 0, 0, 0, 0, 0, 0, 0, 0, 0, 0, 0, 0]}
      Seat1PMMCnvrtScalM3: category=STRUCTURE, type=SeatMMCnvrtScalStrct, init-value={short-label=InitValue_SeatMMCnvrtScalStrct, fields=[1, 1, 1, 1, 1, 1, 1, 1, 1, 1, 1, 1, 1, 1, 1]}
      Seat1PMaxPosM3: category=STRUCTURE, type=SeatAxPosCntStrct, init-value={short-label=InitValue_SeatAxPosCntStrct, fields=[0, 0, 0, 0, 0, 0, 0, 0, 0, 0, 0, 0, 0, 0, 0, 0]}
      Seat1PMinPosM3: category=STRUCTURE, type=SeatAxPosCntStrct, init-value={short-label=InitValue_SeatAxPosCntStrct, fields=[0, 0, 0, 0, 0, 0, 0, 0, 0, 0, 0, 0, 0, 0, 0, 0]}
      Seat1PPctCnvrtOfstM3: category=STRUCTURE, type=SeatPctCnvrtOfstStrct, init-value={short-label=InitValue_SeatMMCnvrtOfstStrct, fields=[0, 0, 0, 0, 0, 0, 0, 0, 0, 0, 0, 0, 0, 0, 0]}
      Seat1PPctCnvrtScalM3: category=STRUCTURE, type=SeatPctCnvrtScalStrct, init-value={short-label=InitValue_SeatMMCnvrtScalStrct, fields=[1, 1, 1, 1, 1, 1, 1, 1, 1, 1, 1, 1, 1, 1, 1]}
      Seat1PPrsHoldDecM3: category=STRUCTURE, type=SeatAxPosCntStrct, init-value={short-label=InitValue_SeatAxPosCntStrct, fields=[0, 0, 0, 0, 0, 0, 0, 0, 0, 0, 0, 0, 0, 0, 0, 0]}
      Seat1PPrsHoldIncM3: category=STRUCTURE, type=SeatAxPosCntStrct, init-value={short-label=InitValue_SeatAxPosCntStrct, fields=[0, 0, 0, 0, 0, 0, 0, 0, 0, 0, 0, 0, 0, 0, 0, 0]}
      Seat1PPrsHoldThldM3: category=VALUE, type=SeatSrvcUint16, init-value=0
      Seat1PTapDecM3: category=STRUCTURE, type=SeatAxPosCntStrct, init-value={short-label=InitValue_SeatAxPosCntStrct, fields=[0, 0, 0, 0, 0, 0, 0, 0, 0, 0, 0, 0, 0, 0, 0, 0]}
      Seat1PTapIncM3: category=STRUCTURE, type=SeatAxPosCntStrct, init-value={short-label=InitValue_SeatAxPosCntStrct, fields=[0, 0, 0, 0, 0, 0, 0, 0, 0, 0, 0, 0, 0, 0, 0, 0]}
      Seat1PTapThldM3: category=STRUCTURE, type=SeatAxPosCntStrct, init-value={short-label=InitValue_SeatAxPosCntStrct, fields=[0, 0, 0, 0, 0, 0, 0, 0, 0, 0, 0, 0, 0, 0, 0, 0]}
      Seat1PVehSpdThldM3: category=VALUE, type=SeatSrvcUint16, init-value=0
      Seat2DDegCnvrtOfstM3: category=STRUCTURE, type=SeatDegCnvrtOfstStrct, init-value={short-label=InitValue_SeatMMCnvrtOfstStrct, fields=[0, 0, 0, 0, 0, 0, 0, 0, 0, 0, 0, 0, 0, 0, 0]}
      Seat2DDegCnvrtScalM3: category=STRUCTURE, type=SeatDegCnvrtScalStrct, init-value={short-label=InitValue_SeatMMCnvrtScalStrct, fields=[1, 1, 1, 1, 1, 1, 1, 1, 1, 1, 1, 1, 1, 1, 1]}
      Seat2DMMCnvrtOfstM3: category=STRUCTURE, type=SeatMMCnvrtOfstStrct, init-value={short-label=InitValue_SeatMMCnvrtOfstStrct, fields=[0, 0, 0, 0, 0, 0, 0, 0, 0, 0, 0, 0, 0, 0, 0]}
      Seat2DMMCnvrtScalM3: category=STRUCTURE, type=SeatMMCnvrtScalStrct, init-value={short-label=InitValue_SeatMMCnvrtScalStrct, fields=[1, 1, 1, 1, 1, 1, 1, 1, 1, 1, 1, 1, 1, 1, 1]}
      Seat2DMaxPosM3: category=STRUCTURE, type=SeatAxPosCntStrct, init-value={short-label=InitValue_SeatAxPosCntStrct, fields=[0, 0, 0, 0, 0, 0, 0, 0, 0, 0, 0, 0, 0, 0, 0, 0]}
      Seat2DMinPosM3: category=STRUCTURE, type=SeatAxPosCntStrct, init-value={short-label=InitValue_SeatAxPosCntStrct, fields=[0, 0, 0, 0, 0, 0, 0, 0, 0, 0, 0, 0, 0, 0, 0, 0]}
      Seat2DPctCnvrtOfstM3: category=STRUCTURE, type=SeatPctCnvrtOfstStrct, init-value={short-label=InitValue_SeatMMCnvrtOfstStrct, fields=[0, 0, 0, 0, 0, 0, 0, 0, 0, 0, 0, 0, 0, 0, 0]}
      Seat2DPctCnvrtScalM3: category=STRUCTURE, type=SeatPctCnvrtScalStrct, init-value={short-label=InitValue_SeatMMCnvrtScalStrct, fields=[1, 1, 1, 1, 1, 1, 1, 1, 1, 1, 1, 1, 1, 1, 1]}
      Seat2DPrsHoldDecM3: category=STRUCTURE, type=SeatAxPosCntStrct, init-value={short-label=InitValue_SeatAxPosCntStrct, fields=[0, 0, 0, 0, 0, 0, 0, 0, 0, 0, 0, 0, 0, 0, 0, 0]}
      Seat2DPrsHoldIncM3: category=STRUCTURE, type=SeatAxPosCntStrct, init-value={short-label=InitValue_SeatAxPosCntStrct, fields=[0, 0, 0, 0, 0, 0, 0, 0, 0, 0, 0, 0, 0, 0, 0, 0]}
      Seat2DPrsHoldThldM3: category=VALUE, type=SeatSrvcUint16, init-value=0
      Seat2DTapDecM3: category=STRUCTURE, type=SeatAxPosCntStrct, init-value={short-label=InitValue_SeatAxPosCntStrct, fields=[0, 0, 0, 0, 0, 0, 0, 0, 0, 0, 0, 0, 0, 0, 0, 0]}
      Seat2DTapIncM3: category=STRUCTURE, type=SeatAxPosCntStrct, init-value={short-label=InitValue_SeatAxPosCntStrct, fields=[0, 0, 0, 0, 0, 0, 0, 0, 0, 0, 0, 0, 0, 0, 0, 0]}
      Seat2DTapThldM3: category=STRUCTURE, type=SeatAxPosCntStrct, init-value={short-label=InitValue_SeatAxPosCntStrct, fields=[0, 0, 0, 0, 0, 0, 0, 0, 0, 0, 0, 0, 0, 0, 0, 0]}
      Seat2DVehSpdThldM3: category=VALUE, type=SeatSrvcUint16, init-value=0
      Seat2PDegCnvrtOfstM3: category=STRUCTURE, type=SeatDegCnvrtOfstStrct, init-value={short-label=InitValue_SeatMMCnvrtOfstStrct, fields=[0, 0, 0, 0, 0, 0, 0, 0, 0, 0, 0, 0, 0, 0, 0]}
      Seat2PDegCnvrtScalM3: category=STRUCTURE, type=SeatDegCnvrtScalStrct, init-value={short-label=InitValue_SeatMMCnvrtScalStrct, fields=[1, 1, 1, 1, 1, 1, 1, 1, 1, 1, 1, 1, 1, 1, 1]}
      Seat2PMMCnvrtOfstM3: category=STRUCTURE, type=SeatMMCnvrtOfstStrct, init-value={short-label=InitValue_SeatMMCnvrtOfstStrct, fields=[0, 0, 0, 0, 0, 0, 0, 0, 0, 0, 0, 0, 0, 0, 0]}
      Seat2PMMCnvrtScalM3: category=STRUCTURE, type=SeatMMCnvrtScalStrct, init-value={short-label=InitValue_SeatMMCnvrtScalStrct, fields=[1, 1, 1, 1, 1, 1, 1, 1, 1, 1, 1, 1, 1, 1, 1]}
      Seat2PMaxPosM3: category=STRUCTURE, type=SeatAxPosCntStrct, init-value={short-label=InitValue_SeatAxPosCntStrct, fields=[0, 0, 0, 0, 0, 0, 0, 0, 0, 0, 0, 0, 0, 0, 0, 0]}
      Seat2PMinPosM3: category=STRUCTURE, type=SeatAxPosCntStrct, init-value={short-label=InitValue_SeatAxPosCntStrct, fields=[0, 0, 0, 0, 0, 0, 0, 0, 0, 0, 0, 0, 0, 0, 0, 0]}
      Seat2PPctCnvrtOfstM3: category=STRUCTURE, type=SeatPctCnvrtOfstStrct, init-value={short-label=InitValue_SeatMMCnvrtOfstStrct, fields=[0, 0, 0, 0, 0, 0, 0, 0, 0, 0, 0, 0, 0, 0, 0]}
      Seat2PPctCnvrtScalM3: category=STRUCTURE, type=SeatPctCnvrtScalStrct, init-value={short-label=InitValue_SeatMMCnvrtScalStrct, fields=[1, 1, 1, 1, 1, 1, 1, 1, 1, 1, 1, 1, 1, 1, 1]}
      Seat2PPrsHoldDecM3: category=STRUCTURE, type=SeatAxPosCntStrct, init-value={short-label=InitValue_SeatAxPosCntStrct, fields=[0, 0, 0, 0, 0, 0, 0, 0, 0, 0, 0, 0, 0, 0, 0, 0]}
      Seat2PPrsHoldIncM3: category=STRUCTURE, type=SeatAxPosCntStrct, init-value={short-label=InitValue_SeatAxPosCntStrct, fields=[0, 0, 0, 0, 0, 0, 0, 0, 0, 0, 0, 0, 0, 0, 0, 0]}
      Seat2PPrsHoldThldM3: category=VALUE, type=SeatSrvcUint16, init-value=0
      Seat2PTapDecM3: category=STRUCTURE, type=SeatAxPosCntStrct, init-value={short-label=InitValue_SeatAxPosCntStrct, fields=[0, 0, 0, 0, 0, 0, 0, 0, 0, 0, 0, 0, 0, 0, 0, 0]}
      Seat2PTapIncM3: category=STRUCTURE, type=SeatAxPosCntStrct, init-value={short-label=InitValue_SeatAxPosCntStrct, fields=[0, 0, 0, 0, 0, 0, 0, 0, 0, 0, 0, 0, 0, 0, 0, 0]}
      Seat2PTapThldM3: category=STRUCTURE, type=SeatAxPosCntStrct, init-value={short-label=InitValue_SeatAxPosCntStrct, fields=[0, 0, 0, 0, 0, 0, 0, 0, 0, 0, 0, 0, 0, 0, 0, 0]}
      Seat2PVehSpdThldM3: category=VALUE, type=SeatSrvcUint16, init-value=0
      SeatCpbltyStrctCfgM3: category=STRUCTURE, type=SeatCpbltyStrct, init-value={short-label=InitValue_SeatCpbltyStrct, fields=[0, 0, 0, 0, 0, 0, 0]}
      SeatRelPrioMaxCfgM3: category=VALUE, type=SeatSrvcUint16, init-value=0
      SeatRelPrioMinCfgM3: category=VALUE, type=SeatSrvcUint16, init-value=0
      actuationDutyCycleMaxCfgM3: category=VALUE, type=SeatSrvcUint8, init-value=0
      actuationDutyCycleMinCfgM3: category=VALUE, type=SeatSrvcUint8, init-value=0
  5 x sender receiver interface:
    SeatAxStatStrctInterface
      data DeSeatAxStatStrct: category=STRUCTURE, sw-calibration-access=READ-ONLY, type=SeatAxisStatStrct
      data DeSeatAxPosStrct: category=STRUCTURE, sw-calibration-access=READ-ONLY, type=SeatAxPosCntStrct
    VehSpd
      data DeVal: category=VALUE, sw-calibration-access=READ-ONLY, type=UInt16_0to500
    seatMultifunctionButtonPressChangedInterface
      data seatMultifunctionButtonPressChanged: category=STRUCTURE, sw-calibration-access=READ-ONLY, type=SeatsTargetAxisStruct
    seatPositionChangedInterface
      data seatPositionChanged: category=STRUCTURE, sw-calibration-access=READ-ONLY, type=SeatAxPosStrct
    seatPositionStatusChangedInterface
      data seatPositionStatusChanged: category=STRUCTURE, sw-calibration-access=READ-ONLY, type=SeatAxisStatStrct
